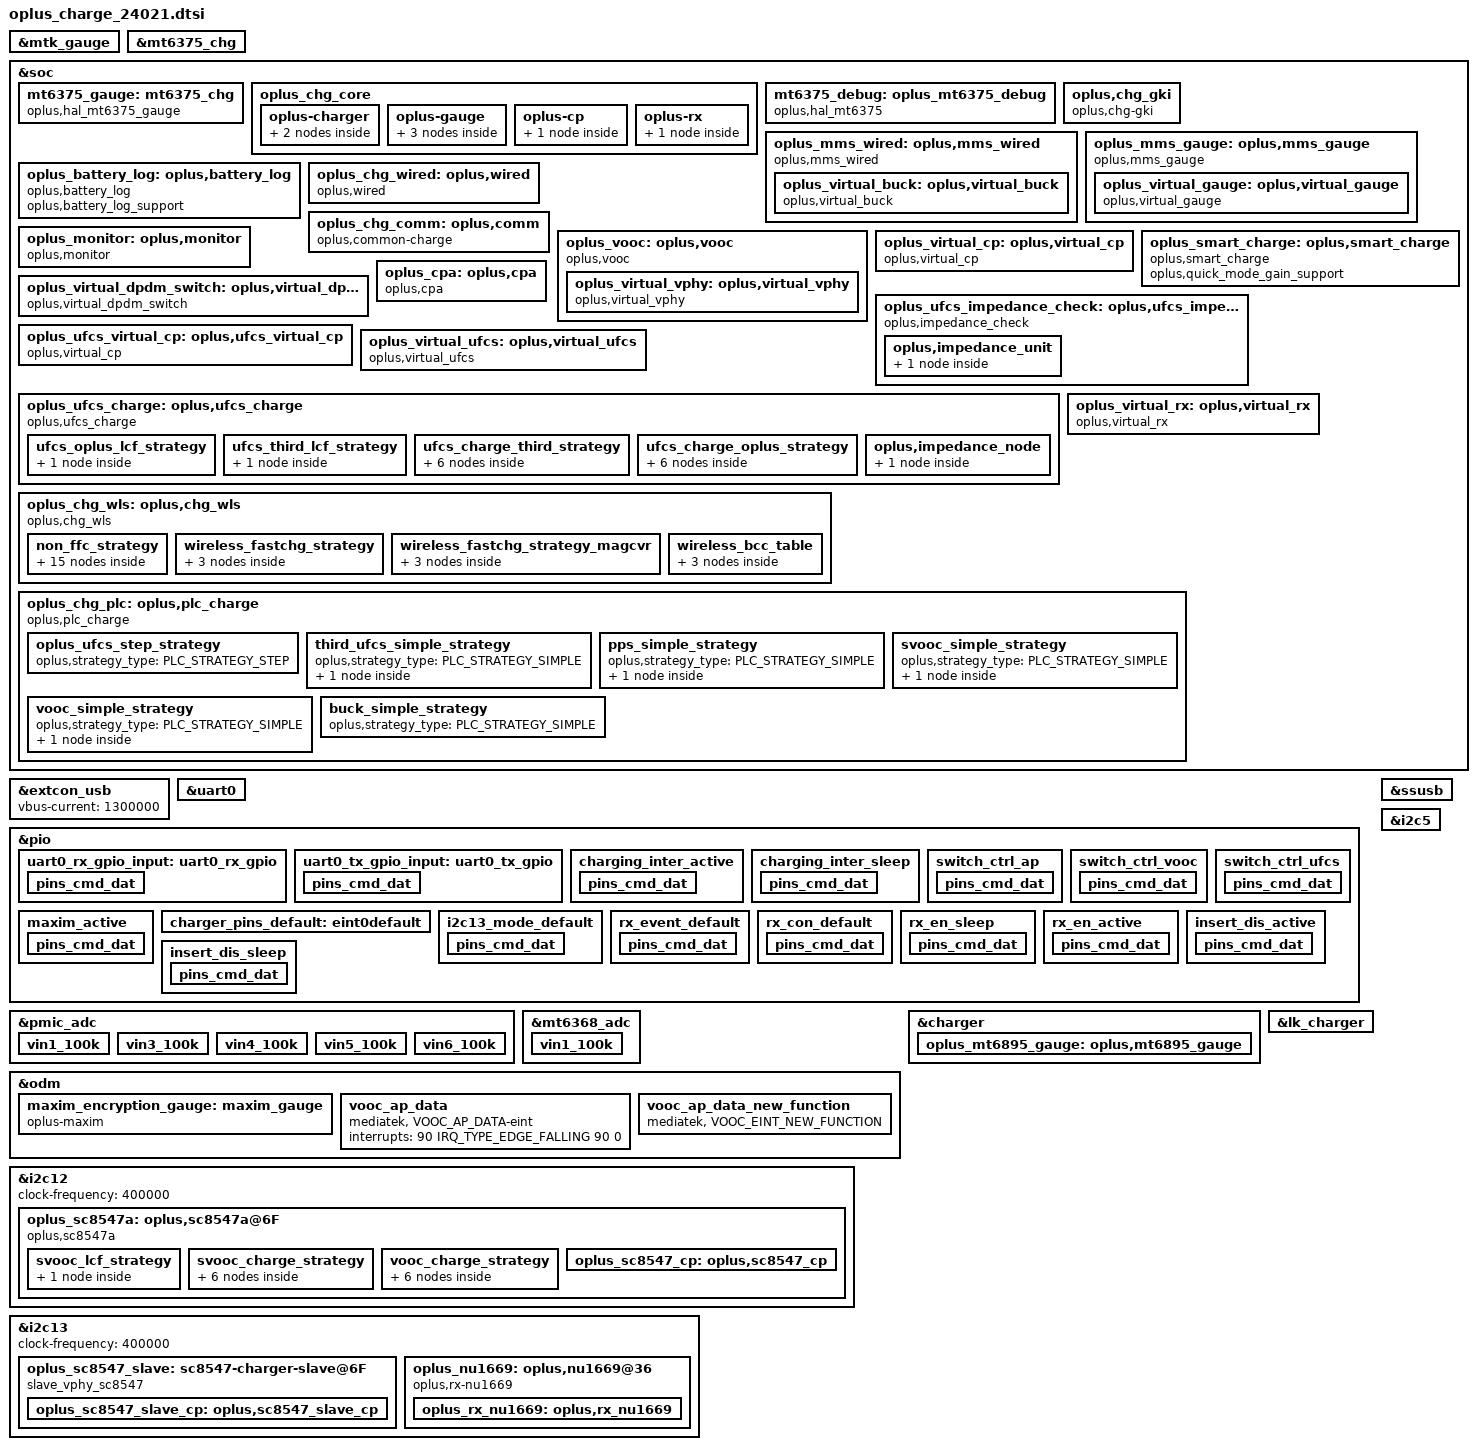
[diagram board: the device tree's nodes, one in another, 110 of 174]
// SPDX-License-Identifier: GPL-2.0-only
/*
* Copyright (C) 2021-2020 Oplus. All rights reserved.
*/
#include <dt-bindings/iio/mt635x-auxadc.h>
#include <dt-bindings/pinctrl/mt6373-pinfunc.h>
#include <dt-bindings/pinctrl/mt65xx.h>
#include "oplus_chg.h"
#include "oplus-chg-24021-fw.dtsi"

&mtk_gauge {
	status = "okay";
	charger = <&mt6375_chg>;
	FUELGAGUE_APPLY = <(1)>;
	IS_SUBBOARD_TEMP_SUPPORT = <(0)>;
	EXTERNAL_AUTHENTICATE =<(1)>;
	Enable_Is_Force_Full = <(1)>;

	active-table = <(5)>;
	r-fg-value = <(1)>;/* R_sense resistance. evb1 use 2; evb2 and later use 1 milliohm */
	com-r-fg-value = <(0)>;/* R_sense compensate resistance. not use COM_R_FG_VALUE */
	RBAT_PULL_DOWN_R = <(24000)>;
	RBAT_PULL_UP_R = <(12000)>;
	RBAT_PULL_UP_VOLT = <(2800)>;
	USE_MORE_PRECISE_NTC_TABLE = <(1)>;
	car-tune-value = <(109)>;
	DIM2_TABLE_DISTINGUISH = <(1)>;
	keep-100-percent-minsoc = <(9500)>;
	aging-factor-diff = <(1)>;
	keep-100-percent = <(2)>;

	#include "bat_setting/mt6897_battery_prop_dim2_ext_24021.dtsi"
	#include "bat_setting/mt6897_battery_table_24021.dtsi"
};

&mt6375_chg {
	chg-tmr = <15>;
	ircmp_v = <0>;
};

&soc {
	mt6375_gauge: mt6375_chg {
		status = "okay";
		compatible = "oplus,hal_mt6375_gauge";

		oplus,ic_type = <OPLUS_CHG_IC_GAUGE>;
		oplus,ic_index = <0>;
		oplus,batt_num = <1>;
		oplus,mtk_gauge_power_sel_support;
		oplus,mtk_gauge_cali_track_support;
	};
};

&extcon_usb {
	vbus-current = <1300000>;
};

&uart0 {
	pinctrl-names = "uart0_rx_gpio", "uart0_tx_gpio";
	pinctrl-0 = <&uart0_rx_gpio_input>;
	pinctrl-1 = <&uart0_tx_gpio_input>;
	status = "okay";
	txpin = <207>;
	rxpin = <208>;
};

&pio {
	uart0_rx_gpio_input: uart0_rx_gpio {
		pins_cmd_dat {
			pinmux = <PINMUX_GPIO208__FUNC_GPIO208>; /* URXD0 */
			input-enable;
			bias-disable;
		};
	};

	uart0_tx_gpio_input: uart0_tx_gpio {
		pins_cmd_dat {
			pinmux = <PINMUX_GPIO207__FUNC_GPIO207>; /* UTXD0 */
			input-enable;
			bias-disable;
		};
	};
};

&pmic_adc {
	vin1_100k {
		channel = <AUXADC_VIN1>;
		pures = <ADC_PURES_100K>;
	};
	vin3_100k {
		channel = <AUXADC_VIN3>;
		pures = <ADC_PURES_100K>;
	};
	vin4_100k {
		channel = <AUXADC_VIN4>;
		pures = <ADC_PURES_100K>;
	};
	vin5_100k {
		channel = <AUXADC_VIN5>;
		pures = <ADC_PURES_100K>;
	};
	vin6_100k {
		channel = <AUXADC_VIN6>;
		pures = <ADC_PURES_100K>;
	};
};

&mt6368_adc {
        vin1_100k {
                channel = <AUXADC_VIN1>;
                pures = <ADC_PURES_100K>;
        };
};

&pio {
	charging_inter_active: charging_inter_active {
		pins_cmd_dat {
			pinmux = <PINMUX_GPIO40__FUNC_GPIO40>;
			input-enable;
			bias-pull-up;
		};
	};

	charging_inter_sleep: charging_inter_sleep {
		pins_cmd_dat {
			pinmux = <PINMUX_GPIO40__FUNC_GPIO40>;
			input-enable;
			bias-disable;
		};
	};
	
	switch_ctrl_ap: switch_ctrl_ap {
		pins_cmd_dat {
			pinmux = <PINMUX_GPIO128__FUNC_GPIO128>;
			output-low;
		};
	};

	switch_ctrl_vooc: switch_ctrl_vooc {
		pins_cmd_dat {
			pinmux = <PINMUX_GPIO128__FUNC_GPIO128>;
			output-high;
		};
	};

	switch_ctrl_ufcs: switch_ctrl_ufcs {
		pins_cmd_dat {
			pinmux = <PINMUX_GPIO128__FUNC_GPIO128>;
			output-high;
		};
	};
};

&soc {
	oplus_chg_core {
		oplus,chg_framework_v2;
		oplus,smart_charging_screenoff;
		oplus,chg_spec_version = <OPLUS_CHG_SPEC_VER_V3P7>;
		oplus,common-charge-icl-support;

		oplus-charger {
			mtk_6895_groups: oplus,mtk_6895-groups {
				functions = <
					OPLUS_IC_FUNC_INIT
					OPLUS_IC_FUNC_EXIT
					OPLUS_IC_FUNC_REG_DUMP
					OPLUS_IC_FUNC_SMT_TEST
					OPLUS_IC_FUNC_BUCK_INPUT_PRESENT
					OPLUS_IC_FUNC_BUCK_INPUT_SUSPEND
					OPLUS_IC_FUNC_BUCK_INPUT_IS_SUSPEND
					OPLUS_IC_FUNC_BUCK_OUTPUT_SUSPEND
					OPLUS_IC_FUNC_BUCK_OUTPUT_IS_SUSPEND
					OPLUS_IC_FUNC_BUCK_SET_ICL
					OPLUS_IC_FUNC_BUCK_GET_ICL
					OPLUS_IC_FUNC_BUCK_SET_FCC
					OPLUS_IC_FUNC_BUCK_SET_FV
					OPLUS_IC_FUNC_BUCK_SET_ITERM
					OPLUS_IC_FUNC_BUCK_GET_INPUT_CURR
					OPLUS_IC_FUNC_BUCK_GET_INPUT_VOL
					OPLUS_IC_FUNC_OTG_BOOST_ENABLE
					OPLUS_IC_FUNC_BUCK_GET_CC_ORIENTATION
					OPLUS_IC_FUNC_BUCK_GET_CHARGER_TYPE
					OPLUS_IC_FUNC_BUCK_RERUN_BC12
					OPLUS_IC_FUNC_BUCK_QC_DETECT_ENABLE
					OPLUS_IC_FUNC_BUCK_SET_QC_CONFIG
					OPLUS_IC_FUNC_BUCK_SET_PD_CONFIG
					OPLUS_IC_FUNC_GET_SHUTDOWN_SOC
					OPLUS_IC_FUNC_BACKUP_SOC
					OPLUS_IC_FUNC_GET_TYPEC_MODE
					OPLUS_IC_FUNC_SET_TYPEC_MODE
					OPLUS_IC_FUNC_GET_TYPEC_ROLE
					OPLUS_IC_FUNC_BUCK_GET_USB_AICL_ENHANCE
					OPLUS_IC_FUNC_BUCK_SET_VINDPM
					OPLUS_IC_FUNC_GET_OTG_ENABLE
					OPLUS_IC_FUNC_BUCK_GET_HW_DETECT
					OPLUS_IC_FUNC_SET_USB_DISCHG_ENABLE
					OPLUS_IC_FUNC_GET_USB_DISCHG_STATUS
					OPLUS_IC_FUNC_IS_OPLUS_SVID
					OPLUS_IC_FUNC_BUCK_GET_USB_BTB_TEMP
					OPLUS_IC_FUNC_BUCK_GET_BATT_BTB_TEMP
					OPLUS_IC_FUNC_BUCK_SET_AICL_POINT
					OPLUS_IC_FUNC_SET_OTG_BOOST_CURR_LIMIT
					OPLUS_IC_FUNC_SET_OTG_BOOST_VOL
					OPLUS_IC_FUNC_BUCK_GET_FV
					OPLUS_IC_FUNC_BUCK_GET_TYPEC_STATE
					OPLUS_IC_FUNC_WLS_BOOST_ENABLE
					OPLUS_IC_FUNC_SET_WLS_BOOST_VOL
					OPLUS_IC_FUNC_SET_WLS_BOOST_CURR_LIMIT
					OPLUS_IC_FUNC_BUCK_WLS_INPUT_SUSPEND
					OPLUS_IC_FUNC_BUCK_SET_WLS_ICL
					OPLUS_IC_FUNC_BUCK_GET_WLS_ICL
					OPLUS_IC_FUNC_BUCK_GET_WLS_INPUT_CURR
					OPLUS_IC_FUNC_BUCK_GET_WLS_INPUT_VOL
					OPLUS_IC_FUNC_BUCK_WLS_AICL_ENABLE
					OPLUS_IC_FUNC_BUCK_WLS_AICL_RERUN
					OPLUS_IC_FUNC_BUCK_DIS_INSERT_DETECT
				>;
				virqs = <
					OPLUS_IC_VIRQ_ERR
					OPLUS_IC_VIRQ_CC_DETECT
					OPLUS_IC_VIRQ_PLUGIN
					OPLUS_IC_VIRQ_CC_CHANGED
					OPLUS_IC_VIRQ_CHG_TYPE_CHANGE
					OPLUS_IC_VIRQ_OTG_ENABLE
					OPLUS_IC_VIRQ_SVID
					OPLUS_IC_VIRQ_TYPEC_STATE
				>;
			};


			mt6375_debug_groups: oplus,mt6375_debug_groups {
				functions = <
					OPLUS_IC_FUNC_INIT
					OPLUS_IC_FUNC_EXIT
				>;
				virqs = <
					OPLUS_IC_VIRQ_ERR
				>;
			};
		};

		oplus-gauge {
			mt6375_gauge_groups: oplus,mt6375_gauge_groups {
				functions = <
					OPLUS_IC_FUNC_INIT
					OPLUS_IC_FUNC_EXIT
					OPLUS_IC_FUNC_REG_DUMP
					OPLUS_IC_FUNC_SMT_TEST
					OPLUS_IC_FUNC_GAUGE_GET_BATT_VOL
					OPLUS_IC_FUNC_GAUGE_GET_BATT_MAX
					OPLUS_IC_FUNC_GAUGE_GET_BATT_MIN
					OPLUS_IC_FUNC_GAUGE_GET_BATT_CURR
					OPLUS_IC_FUNC_GAUGE_GET_BATT_TEMP
					OPLUS_IC_FUNC_GAUGE_GET_BATT_SOC
					OPLUS_IC_FUNC_GAUGE_GET_BATT_FCC
					OPLUS_IC_FUNC_GAUGE_GET_BATT_CC
					OPLUS_IC_FUNC_GAUGE_GET_BATT_RM
					OPLUS_IC_FUNC_GAUGE_GET_BATT_SOH
					OPLUS_IC_FUNC_GAUGE_GET_BATT_HMAC
					OPLUS_IC_FUNC_GAUGE_SET_BATT_FULL
					OPLUS_IC_FUNC_GAUGE_UPDATE_DOD0
					OPLUS_IC_FUNC_GAUGE_UPDATE_SOC_SMOOTH
					OPLUS_IC_FUNC_GAUGE_GET_CB_STATUS
					OPLUS_IC_FUNC_GAUGE_GET_BATT_NUM
					OPLUS_IC_FUNC_GAUGE_GET_DEVICE_TYPE
					OPLUS_IC_FUNC_GAUGE_GET_DEVICE_TYPE_FOR_VOOC
					OPLUS_IC_FUNC_GAUGE_GET_BATT_FCC
					OPLUS_IC_FUNC_GAUGE_GET_BATT_FC
					OPLUS_IC_FUNC_GAUGE_GET_BATT_QM
					OPLUS_IC_FUNC_GAUGE_GET_BATT_PD
					OPLUS_IC_FUNC_GAUGE_GET_BATT_RCU
					OPLUS_IC_FUNC_GAUGE_GET_BATT_RCF
					OPLUS_IC_FUNC_GAUGE_GET_BATT_FCU
					OPLUS_IC_FUNC_GAUGE_GET_BATT_FCF
					OPLUS_IC_FUNC_GAUGE_GET_BATT_SOU
					OPLUS_IC_FUNC_GAUGE_GET_BATT_DO0
					OPLUS_IC_FUNC_GAUGE_GET_BATT_DOE
					OPLUS_IC_FUNC_GAUGE_GET_BATT_TRM
					OPLUS_IC_FUNC_GAUGE_GET_BATT_PC
					OPLUS_IC_FUNC_GAUGE_GET_BATT_QS
					OPLUS_IC_FUNC_GAUGE_IS_SUSPEND
					OPLUS_IC_FUNC_GAUGE_GET_BCC_PARMS
					OPLUS_IC_FUNC_GAUGE_FASTCHG_UPDATE_BCC_PARMS
					OPLUS_IC_FUNC_GAUGE_GET_PREV_BCC_PARMS
					OPLUS_IC_FUNC_GAUGE_SET_BCC_PARMS
					OPLUS_IC_FUNC_GAUGE_SET_PROTECT_CHECK
					OPLUS_IC_FUNC_GAUGE_GET_AFI_UPDATE_DONE
					OPLUS_IC_FUNC_GAUGE_CHECK_RESET
					OPLUS_IC_FUNC_GAUGE_GET_DEVICE_TYPE_FOR_BCC
					OPLUS_IC_FUNC_GAUGE_GET_DOD0
					OPLUS_IC_FUNC_GAUGE_GET_DOD0_PASSED_Q
					OPLUS_IC_FUNC_GAUGE_GET_QMAX
					OPLUS_IC_FUNC_GAUGE_GET_QMAX_PASSED_Q
					OPLUS_IC_FUNC_GAUGE_SET_BATTERY_CURVE
					OPLUS_IC_FUNC_GAUGE_GET_GAUGE_CAR_C
				>;
				virqs = <
					OPLUS_IC_VIRQ_ERR
					OPLUS_IC_VIRQ_OFFLINE
					OPLUS_IC_VIRQ_RESUME
				>;
			};

			mt6895_gauge_groups: oplus,mt6895_gauge_groups {
				functions = <
					OPLUS_IC_FUNC_INIT
					OPLUS_IC_FUNC_EXIT
					OPLUS_IC_FUNC_GAUGE_GET_SUBBOARD_TEMP
				>;
				virqs = <
					OPLUS_IC_VIRQ_ERR
				>;
			};

			maxim_encryption_gauge_groups: oplus,maxim_encryption_gauge_groups {
				functions = <
					OPLUS_IC_FUNC_INIT
					OPLUS_IC_FUNC_EXIT
					OPLUS_IC_FUNC_GAUGE_GET_BATT_AUTH
				>;
				virqs = <
					OPLUS_IC_VIRQ_ERR
				>;
			};
		};
		oplus-cp {
			sc8547_cp_groups: oplus,cp_groups {
			functions = <
					OPLUS_IC_FUNC_INIT
					OPLUS_IC_FUNC_EXIT
					OPLUS_IC_FUNC_REG_DUMP
					OPLUS_IC_FUNC_SMT_TEST
					OPLUS_IC_FUNC_CP_ENABLE
					OPLUS_IC_FUNC_CP_HW_INTI
					OPLUS_IC_FUNC_CP_SET_WORK_START
					OPLUS_IC_FUNC_CP_CHECK_WORK_MODE_SUPPORT
					OPLUS_IC_FUNC_CP_SET_WORK_MODE
					OPLUS_IC_FUNC_CP_GET_WORK_MODE
					OPLUS_IC_FUNC_CP_GET_VIN
					OPLUS_IC_FUNC_CP_GET_IIN
					OPLUS_IC_FUNC_CP_SET_IIN
					OPLUS_IC_FUNC_CP_GET_VOUT
					OPLUS_IC_FUNC_CP_GET_IOUT
					OPLUS_IC_FUNC_CP_GET_VAC
					OPLUS_IC_FUNC_CP_GET_WORK_STATUS
					OPLUS_IC_FUNC_CP_SET_ADC_ENABLE
					OPLUS_IC_FUNC_CP_WATCHDOG_ENABLE
					OPLUS_IC_FUNC_CP_SET_UCP_DISABLE
				>;
				virqs = <
					OPLUS_IC_VIRQ_ERR
					OPLUS_IC_VIRQ_ONLINE
					OPLUS_IC_VIRQ_OFFLINE
				>;
			};
		};

		oplus-rx {
			nu1669_rx_groups: oplus,rx_groups {
				functions = <
					OPLUS_IC_FUNC_INIT
					OPLUS_IC_FUNC_EXIT
					OPLUS_IC_FUNC_REG_DUMP
					OPLUS_IC_FUNC_SMT_TEST
					OPLUS_IC_FUNC_RX_SET_ENABLE
					OPLUS_IC_FUNC_RX_IS_ENABLE
					OPLUS_IC_FUNC_RX_IS_CONNECTED
					OPLUS_IC_FUNC_RX_GET_VOUT
					OPLUS_IC_FUNC_RX_SET_VOUT
					OPLUS_IC_FUNC_RX_GET_VRECT
					OPLUS_IC_FUNC_RX_GET_IOUT
					OPLUS_IC_FUNC_RX_GET_TRX_VOL
					OPLUS_IC_FUNC_RX_GET_TRX_CURR
					OPLUS_IC_FUNC_RX_GET_CEP_COUNT
					OPLUS_IC_FUNC_RX_GET_CEP_VAL
					OPLUS_IC_FUNC_RX_GET_WORK_FREQ
					OPLUS_IC_FUNC_RX_GET_RX_MODE
					OPLUS_IC_FUNC_RX_SET_RX_MODE
					OPLUS_IC_FUNC_RX_SET_DCDC_ENABLE
					OPLUS_IC_FUNC_RX_SET_TRX_ENABLE
					OPLUS_IC_FUNC_RX_SET_TRX_START
					OPLUS_IC_FUNC_RX_GET_TRX_STATUS
					OPLUS_IC_FUNC_RX_GET_TRX_ERR
					OPLUS_IC_FUNC_RX_GET_HEADROOM
					OPLUS_IC_FUNC_RX_SET_HEADROOM
					OPLUS_IC_FUNC_RX_SEND_MATCH_Q
					OPLUS_IC_FUNC_RX_SET_FOD_PARM
					OPLUS_IC_FUNC_RX_SEND_MSG
					OPLUS_IC_FUNC_RX_REG_MSG_CALLBACK
					OPLUS_IC_FUNC_RX_GET_RX_VERSION
					OPLUS_IC_FUNC_RX_GET_TRX_VERSION
					OPLUS_IC_FUNC_RX_UPGRADE_FW_BY_BUF
					OPLUS_IC_FUNC_RX_UPGRADE_FW_BY_IMG
					OPLUS_IC_FUNC_RX_CHECK_CONNECT
					OPLUS_IC_FUNC_RX_GET_EVENT_CODE
					OPLUS_IC_FUNC_RX_GET_BRIDGE_MODE
					OPLUS_IC_FUNC_RX_DIS_INSERT
					OPLUS_IC_FUNC_RX_STANDBY_CONFIG
					OPLUS_IC_FUNC_RX_SET_COMU
					OPLUS_IC_FUNC_RX_GET_TX_ID
				>;
				virqs = <
					OPLUS_IC_VIRQ_ERR
					OPLUS_IC_VIRQ_PRESENT
					OPLUS_IC_VIRQ_ONLINE
					OPLUS_IC_VIRQ_OFFLINE
					OPLUS_IC_VIRQ_EVENT_CHANGED
				>;
			};
		};
	};
};

&soc {
	mt6375_debug: oplus_mt6375_debug {
		status = "okay";
		compatible = "oplus,hal_mt6375";

		oplus,tcpc_name = "type_c_port0";

		oplus,ic_type = <OPLUS_CHG_IC_BUCK>;
		oplus,ic_index = <2>;
	};
};

&odm {
	maxim_encryption_gauge: maxim_gauge {
		status = "okay";
		compatible = "oplus-maxim";
		pinctrl-names = "maxim_active";
		pinctrl-0 = <&maxim_active>;
		support_encryption_in_lk;
		data-gpio = <&pio 23 0x00>;
		gpio-addr-set-out = <0x10005004>;
		gpio-addr-set-in = <0x10005008>;
		gpio-addr-level_high = <0x10005104>;
		gpio-addr-level_low = <0x10005108>;
		gpio-addr-data-in = <0x10005200>;
		gpio-addr-offset = <0x17>;

		oplus,batt_info = /bits/ 8 <0x36 0x31 0x31 0x33 0x30 0x33 0x30 0x30 0x30 0x31 0x34 0x35
					    0x36 0x31 0x31 0x33 0x30 0x33 0x30 0x30 0x30 0x31 0x34 0x34>;

		oplus,ic_type = <OPLUS_CHG_IC_GAUGE>;
		oplus,ic_index = <2>;
	};
};

&pio {
	maxim_active: maxim_active {
		pins_cmd_dat {
			pinmux = <PINMUX_GPIO23__FUNC_GPIO23>;
			//slew-rate = <1>;
			drive-strength = <6>;
			bias-pull-up;
		};
	};
};

&soc {
	oplus,chg_gki {
		compatible = "oplus,chg-gki";
	};
};

&charger {
	io-channels = <&mt6368_adc (ADC_PURES_100K_MASK | AUXADC_VIN1)>, <&pmic_adc AUXADC_VIN5>, <&pmic_adc AUXADC_VIN6>, <&pmic_adc AUXADC_VIN1>;
	io-channel-names = "auxadc1-ntc_sub_bat_tem", "auxadc5-chargeric_temp", "auxadc5_batt_btb_temp", "auxadc6_usb_btb_temp";

	pinctrl-names = "default";
	pinctrl-0 = <&charger_pins_default>;
	oplus,support_ntc_01c_precision;
	oplus,support_subboard_ntc;
	max_charger_voltage = <15000000>;
	/* ntc_resistance:100k internal_pull_up:100k voltage:1.84v */
	oplus,ntc_temp_volt_1840mv;

	oplus,usb_aicl_enhance;

	/* usbtemp dischg use pmic regulator to set vbus down */
	oplus,support_usbtemp_dischg_reg_configurable;
	oplus,usbtemp_dischg_reg_addr = <0x989>;
	oplus,usbtemp_dischg_reg_mask = <0x7>;
	oplus,usbtemp_dischg_enable = <0x2>;
	oplus,usbtemp_dischg_disable = <0x0>;

	oplus,ic_type = <OPLUS_CHG_IC_BUCK>;
	oplus,ic_index = <0>;

	oplus_mt6895_gauge: oplus,mt6895_gauge {
		oplus,ic_type = <OPLUS_CHG_IC_GAUGE>;
		oplus,ic_index = <1>;
	};
};

&odm {
	vooc_ap_data:vooc_ap_data {
		compatible = "mediatek, VOOC_AP_DATA-eint";
		interrupts = <90 IRQ_TYPE_EDGE_FALLING 90 0>;
	};
	vooc_ap_data_new_function:vooc_ap_data_new_function {
		compatible = "mediatek, VOOC_EINT_NEW_FUNCTION";
	};
};

&pio {
	charger_pins_default: eint0default {
	};
};

&lk_charger {
	en_vol_ctrl_vibrate = <3200>;
	support_tuv_authentication;
	high-temp-scheme;
	charger_no_wiress;
	support_battery_type = <2>;
	support_maxim_battery_authentication;
	data-gpio = <23>;
	//cpu-id = <7>;
	//key-id = <1>;
	oplus,batt_info = /bits/ 8 <0x36 0x31 0x31 0x33 0x30 0x33 0x30 0x30 0x30 0x31 0x34 0x35
				    0x36 0x31 0x31 0x33 0x30 0x33 0x30 0x30 0x30 0x31 0x34 0x34>;
	oplus,batt_resource_info = /bits/ 8 <0 1>;
	sub_board_temp_support;
	over_high_temp_thr = <60>;
	sub_board_adc_channel = <18>;		/* AUXADC_CHAN_VIN1 in LK, Use the MT6368 PMIC */
	sub_board_adc_pmic = <1>;		/* Vivien use the MT6368 Pmic, in lk2 it's name is "second_pmic_sdmadc" */
	sub_board_adc_pull_up_voltage = <1840>;
	sub_board_adc_pures = <0>;	/* Vivien config as SDMADC_100K */

	support_sdp_screenoff;
	sdp_screenon_voltage = <3250>;
	support_quickboot_charge;
	mt6375_wireless_prj_shipmode_support; /* use MT6375 and support wireless prj,need to configure this to enter shipmode success */

	/* mt6989 start */
	led-brightness = <102>;
	/* mt6989, such as max_charger_voltage to max-charger-voltage */
	max-charger-voltage = <15000000>;
	boot-battery-voltage = <3350000>;
	usb-charger-current = <500000>;
	ac-charger-current = <2050000>;
	ac-charger-input-current = <1500000>;
	non-std-ac-charger-current = <750000>;
	charging-host-charger-current = <1500000>;
	ta-ac-charger-current = <1500000>;
	pd-charger-current = <500000>;
	/* mt6989 end */
};

&soc {
	oplus_mms_wired: oplus,mms_wired {
		compatible = "oplus,mms_wired";
		oplus,buck_ic = <&oplus_virtual_buck>;
		oplus,voocphy_ic = <&oplus_virtual_vphy>;
		oplus,adc_info_name = "100k_1840mv";
		oplus_spec,usbtemp_batttemp_gap = <12>;
		high-temp-scheme;

		/* support for V2.0 usbtemp protect. */
		oplus,support_usbtemp_protect_v2;
		oplus,support_wlsotg_non_coexistence;
		oplus_spec,usbtemp_batt_temp_low = <50>;
		oplus_spec,usbtemp_batt_temp_high = <50>;
		oplus_spec,usbtemp_batt_temp_over_hot = <60>;
		oplus_spec,usbtemp_ntc_temp_low = <57>;
		oplus_spec,usbtemp_ntc_temp_high = <69>;
		oplus_spec,usbtemp_temp_gap_low_with_batt_temp = <7>;
		oplus_spec,usbtemp_temp_gap_with_batt_temp_in_over_hot = <15>;
		oplus_spec,usbtemp_temp_gap_high_with_batt_temp = <12>;
		oplus_spec,usbtemp_temp_gap_low_without_batt_temp = <12>;
		oplus_spec,usbtemp_temp_gap_high_without_batt_temp = <24>;
		oplus_spec.usbtemp_rise_fast_temp_low = <3>;
		oplus_spec.usbtemp_rise_fast_temp_high = <3>;
		oplus_spec.usbtemp_rise_fast_temp_count_low = <30>;
		oplus_spec.usbtemp_rise_fast_temp_count_high = <20>;
		oplus_spec,usbtemp_cool_down_ntc_low = <54>;
		oplus_spec,usbtemp_cool_down_ntc_high = <65>;
		oplus_spec,usbtemp_cool_down_gap_low = <12>;
		oplus_spec,usbtemp_cool_down_gap_high = <20>;
		oplus_spec,usbtemp_cool_down_recover_ntc_low = <48>;
		oplus_spec,usbtemp_cool_down_recover_ntc_high = <60>;
		oplus_spec,usbtemp_cool_down_recover_gap_low = <6>;
		oplus_spec,usbtemp_cool_down_recover_gap_high = <15>;

		oplus_virtual_buck: oplus,virtual_buck {
			compatible = "oplus,virtual_buck";
			oplus,buck_ic = <&charger &mt6375_debug>;
			oplus,buck_ic_index = <0 1>;
			oplus,buck_ic_current_ratio = <100 0>;
			oplus,buck_ic_connect = <OPLUS_CHG_IC_CONNECT_PARALLEL>;
			oplus,main_charger = <0>;
			oplus,buck_ic_func_group = <&mtk_6895_groups &mt6375_debug_groups>;

			oplus,ic_type = <OPLUS_CHG_IC_VIRTUAL_BUCK>;
			oplus,ic_index = <0>;

			io-channels = <&pmic_adc AUXADC_VIN3>, <&pmic_adc AUXADC_VIN4>;
			io-channel-names = "usb_temp_adc_l", "usb_temp_adc_r";

			oplus,uart_tx-gpio = <&pio 207 0x00>;
			oplus,uart_rx-gpio = <&pio 208 0x00>;
		};
	};

	oplus_mms_gauge: oplus,mms_gauge {
		compatible = "oplus,mms_gauge";
		oplus,gauge_ic = <&oplus_virtual_gauge>;
		oplus,voocphy_ic = <&oplus_virtual_vphy>;
		oplus,topic-update-interval = <10000>;
		oplus,support_subboard_ntc;

		oplus_virtual_gauge: oplus,virtual_gauge {
			compatible = "oplus,virtual_gauge";
			oplus,gauge_ic = <&mt6375_gauge &oplus_mt6895_gauge &maxim_encryption_gauge>;
			oplus,gauge_ic_index = <0 1 2>;
			oplus,gauge_ic_func_group = <&mt6375_gauge_groups &mt6895_gauge_groups &maxim_encryption_gauge_groups>;
			oplus,batt_capacity_mah = <5800>;
			oplus,ic_type = <OPLUS_CHG_IC_VIRTUAL_GAUGE>;
			oplus,ic_index = <0>;
		};
	};
};

&soc {
	oplus_battery_log: oplus,battery_log {
		compatible = "oplus,battery_log";

		oplus,battery_log_support;
	};

	oplus_chg_wired: oplus,wired {
		compatible = "oplus,wired";

		oplus,vooc-support;

		oplus_spec,vbatt_pdqc_to_5v_thr = <4500>;
		oplus_spec,vbatt_pdqc_to_9v_thr = <4500>;
		oplus_spec,pd-iclmax-ma = <1500>;
		oplus_spec,qc-iclmax-ma = <1500>;
		oplus_spec,non-standard-ibatmax-ma = <500>;
		oplus_spec,input-power-mw = <
			500	    	/* OPLUS_WIRED_CHG_MODE_UNKNOWN */
			2500		/* OPLUS_WIRED_CHG_MODE_SDP */
			7500		/* OPLUS_WIRED_CHG_MODE_CDP */
			10000		/* OPLUS_WIRED_CHG_MODE_DCP */
			15000		/* OPLUS_WIRED_CHG_MODE_VOOC */
			13500		/* OPLUS_WIRED_CHG_MODE_QC */
			13500		/* OPLUS_WIRED_CHG_MODE_PD */
		>;
		oplus_spec,led_on-fccmax-ma = <0 1443 2538 3300 3300 3300 3300 1000 0>;
		oplus_spec,fccmax-ma-lv = <
			0 1410 2200 2200 2200 2200 2200 2200 0	/* OPLUS_WIRED_CHG_MODE_UNKNOWN */
			0 600  600  600  600  600  600  600  0	/* OPLUS_WIRED_CHG_MODE_SDP */
			0 1410 1600 1600 1600 1600 1600 1600 0	/* OPLUS_WIRED_CHG_MODE_CDP */
			0 1410 2200 2200 2200 2200 2200 2200 0	/* OPLUS_WIRED_CHG_MODE_DCP */
			0 1410 3300 3300 3300 3300 3300 3102 0	/* OPLUS_WIRED_CHG_MODE_VOOC */
			0 1410 3300 3300 3300 3300 3300 3102 0	/* OPLUS_WIRED_CHG_MODE_QC */
			0 1410 3300 3300 3300 3300 3300 3102 0	/* OPLUS_WIRED_CHG_MODE_PD */
		>;
		oplus_spec,fccmax-ma-hv = <
			0 1410 2200 2200 2200 2200 2200 2200 0	/* OPLUS_WIRED_CHG_MODE_UNKNOWN */
			0 600  600  600  600  600  600  600  0	/* OPLUS_WIRED_CHG_MODE_SDP */
			0 1410 1600 1600 1600 1600 1600 1600 0	/* OPLUS_WIRED_CHG_MODE_CDP */
			0 1410 2200 2200 2200 2200 2200 2200 0	/* OPLUS_WIRED_CHG_MODE_DCP */
			0 1410 3300 3300 3300 3300 3300 3102 0	/* OPLUS_WIRED_CHG_MODE_VOOC */
			0 1410 3300 3300 3300 3300 3300 3102 0	/* OPLUS_WIRED_CHG_MODE_QC */
			0 1410 3300 3300 3300 3300 3300 3102 0	/* OPLUS_WIRED_CHG_MODE_PD */
		>;

		oplus_spec,cool_down_sale_pdqc_vol_mv = <5000>;
		oplus_spec,cool_down_sale_pdqc_curr_ma = <1200>;
		oplus_spec,cool_down_pdqc_vol_mv = <5000 5000 5000 9000>;
		oplus_spec,cool_down_pdqc_curr_ma = <1200 1500 2000 1500>;
		oplus_spec,cool_down_vooc_curr_ma = <1200 1500 2000 2500 3000 3000>;
		oplus_spec,cool_down_normal_curr_ma = <1200 1500 2000>;

		oplus_spec,vbus_ov_thr_mv = <11000 11000>;
		oplus_spec,vbus_uv_thr_mv = <4300 4300>;

		/* first data is strategy used temp type */
		oplus,vooc_strategy_name = "cgcl";
		oplus,vooc_strategy_data = <OPLUS_STRATEGY_USE_BATT_TEMP
					    0   350 3000 1 0
					    330 370 3000 2 0
					    350 440 2200 2 1>;
	};

	oplus_chg_comm: oplus,comm {
		compatible = "oplus,common-charge";
		oplus_spec,batt-them-thr = <(-100) 0 50 120 160 350 450 530>;
		oplus_spec,iterm-ma = <292>; /* 4880*0.05+10 */
		oplus_spec,removed_bat_decidegc = <390>; /*-39 degree*/
		oplus_spec,fv-mv = <4490 4490 4490 4490 4490 4490 4470 4130 4130>;
		oplus_spec,sw-fv-mv = <4440 4440 4440 4440 4440 4440 4420 4080 4080>;
		oplus_spec,hw-fv-inc-mv = <0 18 18 18 18 18 18 18 0>;
		oplus_spec,sw-over-fv-mv = <4500 4500 4500 4500 4500 4500 4480 4140 4140>;
		oplus_spec,sw-over-fv-dec-mv = <8>;
		oplus_spec,non-standard-sw-fv-mv = <3930>;
		oplus_spec,non-standard-fv-mv = <3980>;
		oplus_spec,non-standard-hw-fv-inc-mv = <18>;
		oplus_spec,non-standard-sw-over-fv-mv = <3990>;
		oplus_spec,non-standard-vbatdet-mv = <3680>;
		oplus_spec,wired-vbatdet-mv = <0 4190 4290 4390 4390 4390 4370 4030 0>;
		oplus_spec,wls-vbatdet-mv = <0 4190 4290 4390 4390 4390 4370 4030 0>;
		oplus_spec,fcc-gear-thr-mv = <4180>;
		oplus_spec,vbatt-ov-thr-mv = <4600>;

		oplus_spec,full_pre_ffc_judge;
		oplus_spec,full-pre-ffc-mv = <4485>;
		oplus_spec,ffc-temp-thr = <120 210 350 440>;
		oplus_spec,wired-ffc-step-max = <2>;
		oplus_spec,wired-ffc-fv-mv = <4630 4630>;

		oplus_spec,wired-ffc-fv-cutoff-mv = <4560 4550 4515
						     4550 4540 4500>;
		oplus_spec,wired-ffc-fcc-ma = <1500 1500 1500
					       1000 1000 1000>;
		oplus_spec,wired-ffc-fcc-cutoff-ma = <1300 1300 1300
						      900 900 900>;
		/* 2s battery */
		oplus_spec,wls-ffc-step-max = <2>;
		oplus_spec,wls-ffc-fv-mv = <4630 4630>;
		oplus_spec,wls-ffc-fv-cutoff-mv = <4560 4550 4515
						     4550 4540 4500>;
		oplus_spec,wls-ffc-icl-ma = <1150 1150 1150
					     750 750 750>;
		oplus_spec,wls-ffc-fcc-ma = <1500 1500 1500
					     1000 1000 1000>;
		oplus_spec,wls-ffc-fcc-cutoff-ma = <1300 1300 1300
						900 900 900>;
		oplus_spec,vbat_uv_thr_mv = <3300>;
		oplus_spec,vbat_charging_uv_thr_mv = <3200>;

		/*If use subboard NTC as battery temp, config it as 20, otherwise 0 */
		oplus_spec,tbatt_power_off_cali_temp = <0>;
		oplus,vooc_show_ui_soc_decimal;
		oplus_spec,poweroff_high_batt_temp = <720>;
		oplus_spec,poweroff_emergency_batt_temp = <770>;
		oplus,ui_soc_decimal_speedmin = <20>;
		oplus,gauge_stuck_jump_support;
		oplus,gauge_stuck_threshold = <15>;
		oplus,gauge_stuck_time = <50>;
	};

	oplus_monitor: oplus,monitor {
		compatible = "oplus,monitor";
		oplus,topic-update-interval = <60000>;

		track,fast_chg_break_t_thd = <1000>;
		track,general_chg_break_t_thd = <200>;
		track,voocphy_type = <3>;
		track,wired_max_power = <80000>;
		track,wired_fast_chg_scheme = <2>;
	};

	oplus_vooc: oplus,vooc {
		compatible = "oplus,vooc";
		oplus,vooc_ic = <&oplus_virtual_vphy>;

		oplus_spec,vooc_soc_range = <50 75 85>;
		oplus_spec,vooc_temp_range = <50 120 180 350 450>;

		oplus,vooc_data_width = <7>;
		oplus,vooc_curr_max = <CP_CURR_LIMIT_7BIT_15_0A>; /* 80W: 11V 7.3A(IBUS *2) */
		oplus,vooc_power_max_w = <80>;
		oplus,vooc_project = <7>;
		oplus,vooc_curr_table_type = <VOOC_CP_CURR_TABLE>;
		oplus,voocphy_support = <3>; /* AP_DUAL_CP_VOOCPHY */
		oplus,support_fake_vooc_check;
		oplus,subboard_ntc_abnormal_current = <4000>;
		oplus,cp_cooldown_limit_percent_75 = <CP_CURR_LIMIT_7BIT_8_0A>;
		oplus,cp_cooldown_limit_percent_85 = <CP_CURR_LIMIT_7BIT_4_0A>;

		oplus,abnormal_adapter_current = <CP_CURR_LIMIT_7BIT_15_0A CP_CURR_LIMIT_7BIT_15_0A
						CP_CURR_LIMIT_7BIT_12_6A CP_CURR_LIMIT_7BIT_12_6A
						CP_CURR_LIMIT_7BIT_10_0A CP_CURR_LIMIT_7BIT_10_0A
						CP_CURR_LIMIT_7BIT_8_0A CP_CURR_LIMIT_7BIT_8_0A
						CP_CURR_LIMIT_7BIT_6_0A CP_CURR_LIMIT_7BIT_6_0A
						CP_CURR_LIMIT_7BIT_4_0A CP_CURR_LIMIT_7BIT_4_0A>;

		oplus,abnormal_over_80w_adapter_current = <CP_CURR_LIMIT_7BIT_15_0A CP_CURR_LIMIT_7BIT_15_0A
						CP_CURR_LIMIT_7BIT_14_0A CP_CURR_LIMIT_7BIT_14_0A
						CP_CURR_LIMIT_7BIT_12_0A CP_CURR_LIMIT_7BIT_12_0A
						CP_CURR_LIMIT_7BIT_10_0A CP_CURR_LIMIT_7BIT_10_0A
						CP_CURR_LIMIT_7BIT_8_0A CP_CURR_LIMIT_7BIT_8_0A
						CP_CURR_LIMIT_7BIT_6_0A CP_CURR_LIMIT_7BIT_6_0A
						CP_CURR_LIMIT_7BIT_4_0A CP_CURR_LIMIT_7BIT_4_0A>;

		/* first data is strategy used temp type */
		oplus,general_strategy_name = "cgcl";
		oplus,general_strategy_data = < OPLUS_STRATEGY_USE_SHELL_TEMP
						0   385 CP_CURR_LIMIT_7BIT_15_0A 1 0
						375 395 CP_CURR_LIMIT_7BIT_12_6A 2 0
						385 420 CP_CURR_LIMIT_7BIT_8_0A 3 1
						410 440 CP_CURR_LIMIT_7BIT_6_0A 3 2 >;

		oplus,plc_strategy-data = <&buck_simple_strategy &svooc_simple_strategy &vooc_simple_strategy>;
		oplus,plc_strategy-names = "default", "svooc", "vooc";

		oplus,bypass_strategy_name = "cgcl";
		oplus,bypass_strategy_data = <OPLUS_STRATEGY_USE_SHELL_TEMP
						0   350 CP_CURR_LIMIT_7BIT_6_0A  1 0
						340 380 CP_CURR_LIMIT_7BIT_5_0A  2 0
						370 440 CP_CURR_LIMIT_7BIT_4_0A  2 1>;

		oplus_virtual_vphy: oplus,virtual_vphy {
			compatible = "oplus,virtual_vphy";
			oplus,vphy_ic = <&oplus_sc8547a>;
			oplus,dpdm_switch_ic = <&oplus_virtual_dpdm_switch>;

			oplus,ic_type = <OPLUS_CHG_IC_VIRTUAL_VPHY>;
			oplus,ic_index = <0>;
		};
	};

	oplus_virtual_cp: oplus,virtual_cp {
		compatible = "oplus,virtual_cp";

		oplus,ic_type = <OPLUS_CHG_IC_VIRTUAL_CP>;
		oplus,ic_index = <0>;

		oplus,cp_ic = <&oplus_sc8547_cp &oplus_sc8547_slave_cp>;
		oplus,input_curr_max_ma = <3000 3000>;

		oplus,cp_ic_connect = <OPLUS_CHG_IC_CONNECT_PARALLEL>;
		oplus,main_cp = <0>;

		oplus,reg_proc_node;
	};

	oplus_virtual_dpdm_switch: oplus,virtual_dpdm_switch {
		compatible = "oplus,virtual_dpdm_switch";

		oplus,ic_type = <OPLUS_CHG_IC_MISC>;
		oplus,ic_index = <0>;

		oplus,switch_ctrl-gpio = <&pio 128 0x00>;
		pinctrl-names = "switch_ctrl_ap", "switch_ctrl_vooc", "switch_ctrl_ufcs";
		pinctrl-0 = <&switch_ctrl_ap>;
		pinctrl-1 = <&switch_ctrl_vooc>;
		pinctrl-2 = <&switch_ctrl_ufcs>;
	};
	oplus_smart_charge: oplus,smart_charge {
		compatible = "oplus,smart_charge";
		oplus,quick_mode_gain_support;
	};
};

&i2c12 {
	status = "okay";
	clock-frequency = <400000>;
	oplus_sc8547a: oplus,sc8547a@6F {
		status = "okay";
		compatible = "oplus,sc8547a";
		reg = <0x6F>;

		oplus,use_vooc_phy;
		oplus,use_ufcs_phy;
		oplus_spec,irq_gpio = <&pio 40 0x00>;
		interrupt-parent = <&pio>;
		interrupts = <9 0>;

		pinctrl-names = "charging_inter_active", "charging_inter_sleep";
		pinctrl-0 = <&charging_inter_active>;
		pinctrl-1 = <&charging_inter_sleep>;

		oplus,ic_type = <OPLUS_CHG_IC_VPHY>;
		oplus,ic_index = <0>;
		oplus,vooc-version = <VOOC_VERSION_5_0>;

		ocp_reg = <0xd>;
		ovp_reg = <0x36>;/* vbat ovp 4.85v */
		oplus_spec,voocphy_dual_cp_support;
		oplus_spec,slave_cp_enable_thr = <1400>;		//2000-100mA
		oplus_spec,slave_cp_disable_thr_high = <1100>;	//1500+100mA
		oplus_spec,voocphy_current_default = <73>;
		oplus_spec,ap_control_allow;

		oplus_spec,svooc_cool_down_current_limit = <146 20 20 24 30 34 40 44 50 54 60 64 70 74>;
		oplus_spec,vooc_cool_down_current_limit = <73 20 20 24 30 34 40 44 50 54 60 64 70 74>;

		oplus_spec,vooc_multistep_initial_batt_temp = <1000>;
		oplus_spec,vooc_little_cool_temp = <160>;
		oplus_spec,vooc_little_cool_high_temp = <210>;
		oplus_spec,vooc_cool_temp = <120>;
		oplus_spec,vooc_little_cold_temp = <50>;
		oplus_spec,vooc_normal_low_temp = <350>;
		oplus_spec,vooc_strategy_normal_current = <122>;
		oplus_spec,vooc_normal_to_little_cool_current = <100>;
		oplus_spec,vooc_over_high_temp = <510>;
		oplus_spec,vooc_low_temp = <0>;

		oplus_spec,vooc_high_temp = <500>;
		oplus_spec,vooc_low_soc = <0>;
		oplus_spec,vooc_high_soc = <95>;
		oplus_spec,vooc_normal_high_temp = <440>;
		oplus_spec,vooc_warm_vol_thr = <4000>;
		oplus_spec,vooc_warm_soc_thr = <50>;

		oplus_spec,vooc_strategy1_batt_high_temp0 = <385>;
		oplus_spec,vooc_strategy1_batt_high_temp1 = <395>;
		oplus_spec,vooc_strategy1_batt_high_temp2 = <420>;
		oplus_spec,vooc_strategy1_batt_low_temp2 = <410>;
		oplus_spec,vooc_strategy1_batt_low_temp1 = <385>;
		oplus_spec,vooc_strategy1_batt_low_temp0 = <375>;

		oplus_spec,vooc_strategy1_high_current0 = <80>;
		oplus_spec,vooc_strategy1_high_current1 = <61>;
		oplus_spec,vooc_strategy1_high_current2 = <40>;
		oplus_spec,vooc_strategy1_low_current2 = <40>;
		oplus_spec,vooc_strategy1_low_current1 = <61>;
		oplus_spec,vooc_strategy1_low_current0 = <80>;

		oplus_spec,voocphy_freq_mincore = <925000>;
		oplus_spec,voocphy_freq_midcore = <1718000>;
		oplus_spec,voocphy_freq_maxcore = <1718000>;
		oplus_spec,voocphy_current_change_timeout = <100>;
		oplus_spec,copycat_vooc_support;
		oplus_spec,copycat_vooc_accuracy_value = <105>;

		oplus_spec,fastchg_timeout_time_init = <145020>;
		oplus_spec,voocphy_ibat_over_current = <16000>;
		oplus_spec,voocphy_svooc_cp_max_ibus = <4500>;
		oplus_spec,voocphy_vooc_cp_max_ibus = <4500>;
		oplus_spec,voocphy_cp_max_ibus = <4500>;

		oplus_spec,vooc_little_cold_full_voltage = <4570>;
		oplus_spec,vooc_cool_full_voltage = <4570>;
		oplus_spec,vooc_little_cool_full_voltage = <4570>;
		oplus_spec,vooc_little_cool_high_full_voltage = <4570>;
		oplus_spec,vooc_warm_full_voltage = <4130>;
		oplus_spec,vooc_1time_full_voltage = <4580>;
		oplus_spec,vooc_ntime_full_voltage = <4570>;
		oplus_spec,soc_range = <0 20 35 55 75 85 95>;

		svooc_batt_sys_curve = <0 1 0 1 0 0 0	// 4000mA
					1 1 1 1 0 0 0	// 4604mV
					0 0 1 1 0 1 0	// 2600mA
					1 1 1 1 0 0 0	// 4604mV
					0 0 0 1 0 1 1	// 1100mA
					1 1 1 1 0 0 0>;	// 4604mV

		vooc_batt_sys_curve =  <0 1 0 1 0 0 0	// 4000mA
					1 1 1 1 0 0 0	// 4604mV
					0 0 1 1 0 1 0	// 2600mA
					1 1 1 1 0 0 0	// 4604mV
					0 0 0 1 0 1 1	// 1100mA
					1 1 1 1 0 0 0>;	// 4604mV

		svooc_lcf_strategy {
			oplus,temp_type = <OPLUS_STRATEGY_USE_SHELL_TEMP>;
			oplus,temp_range = <0 50 120 160 210 380 440>;

			strategy_temp_range_curves {
				strategy_temp_range_t0 =	<620 4570 0
								 595 4560 0
								 570 4550 0
								 545 4540 0
								 520 4530 1>;
				strategy_temp_range_t1 =	<1250 4570 0
								 1200 4565 0
								 1150 4550 0
								 1050 4540 0
								 950 4530 1>;
				strategy_temp_range_t2 =	<2150 4570 0
								 2100 4565 0
								 2000 4550 0
								 1900 4540 0
								 1750 4530 1>;
				strategy_temp_range_t3 =	<3200 4568 0
								 3000 4565 0
								 2400 4560 0
								 2000 4555 0
								 1500 4545 1>;
				strategy_temp_range_t4 =	<3200 4568 0
								 3000 4565 0
								 2400 4560 0
								 2000 4555 0
								 1500 4545 1>;
				strategy_temp_range_t5 =	<4100 4560 0
								 3700 4550 0
								 3000 4540 0
								 2400 4530 0
								 2000 4520 1>;
			};
		};

		svooc_charge_strategy {
			strategy_soc_0_to_50 { /* 0 ~ 20 */
				strategy_temp_little_cold =	<4150 25 0 0 0
								4280 20 0 0 0
								4560 15 0 0 0
								4570 10 1 0 0>;
				strategy_temp_cool =		<4150 35 0 0 0
								4150 30 0 0 0
								4280 25 0 0 0
								4560 20 0 0 0
								4560 15 0 0 0
								4570 10 1 0 0>;
				strategy_temp_little_cool =	<4150 61 0 840 0
								4150 50 0 0 0
								4510 47 0 0 0
								4510 45 0 0 0
								4510 40 0 0 0
								4560 39 0 0 0
								4560 35 0 0 0
								4560 30 0 0 0
								4560 25 0 0 0
								4560 20 0 0 0
								4560 15 0 0 0
								4570 11 1 0 0>;
				strategy_temp_little_cool_high =	<4180 73 0 0 0
								4280 62 0 0 0
								4280 50 0 0 0
								4510 49 0 0 0
								4510 40 0 0 0
								4560 36 0 0 0
								4560 35 0 0 0
								4560 30 0 0 0
								4560 25 0 0 0
								4560 20 0 0 0
								4565 18 0 0 0
								4565 15 0 0 0
								4560 10 1 0 0>;
				strategy_temp_normal_low =	<4180 73 0 100 0
								4280 62 0 240 0
								4280 50 0 0 0
								4510 49 0 0 0
								4510 40 0 0 0
								4560 36 0 0 0
								4560 35 0 0 0
								4560 30 0 0 0
								4560 25 0 0 0
								4560 20 0 0 0
								4565 18 0 0 0
								4565 15 0 0 0
								4560 10 1 0 0>;
				strategy_temp_normal_high =	<4180 73 0 100 0
								4280 62 0 240 0
								4280 50 0 0 0
								4510 49 0 0 0
								4510 40 0 0 0
								4560 36 0 0 0
								4560 35 0 0 0
								4560 30 0 0 0
								4560 25 0 0 0
								4565 22 0 0 0
								4550 15 0 0 0
								4530 10 1 0 0>;
				strategy_temp_warm =		<4120 15 0 0 0
								4130 10 1 0 0>;
			};

			strategy_soc_0_to_50_mid { /* 21 ~ 35 */
				strategy_temp_little_cold =	<4150 25 0 0 0
								4280 20 0 0 0
								4560 15 0 0 0
								4570 10 1 0 0>;
				strategy_temp_cool =		<4150 35 0 0 0
								4150 30 0 0 0
								4280 25 0 0 0
								4560 20 0 0 0
								4560 15 0 0 0
								4570 10 1 0 0>;
				strategy_temp_little_cool =	<4150 61 0 840 0
								4150 50 0 0 0
								4510 47 0 0 0
								4510 45 0 0 0
								4510 40 0 0 0
								4560 39 0 0 0
								4560 35 0 0 0
								4560 30 0 0 0
								4560 25 0 0 0
								4560 20 0 0 0
								4560 15 0 0 0
								4570 11 1 0 0>;
				strategy_temp_little_cool_high =	<4180 73 0 0 0
								4280 62 0 0 0
								4280 50 0 0 0
								4510 49 0 0 0
								4510 40 0 0 0
								4560 36 0 0 0
								4560 35 0 0 0
								4560 30 0 0 0
								4560 25 0 0 0
								4560 20 0 0 0
								4565 18 0 0 0
								4565 15 0 0 0
								4560 10 1 0 0>;
				strategy_temp_normal_low =	<4180 73 0 100 0
								4280 62 0 240 0
								4280 50 0 0 0
								4510 49 0 0 0
								4510 40 0 0 0
								4560 36 0 0 0
								4560 35 0 0 0
								4560 30 0 0 0
								4560 25 0 0 0
								4560 20 0 0 0
								4565 18 0 0 0
								4565 15 0 0 0
								4560 10 1 0 0>;
				strategy_temp_normal_high =	<4180 73 0 100 0
								4280 62 0 240 0
								4280 50 0 0 0
								4510 49 0 0 0
								4510 40 0 0 0
								4560 36 0 0 0
								4560 35 0 0 0
								4560 30 0 0 0
								4560 25 0 0 0
								4565 22 0 0 0
								4550 15 0 0 0
								4530 10 1 0 0>;
				strategy_temp_warm =		<4120 15 0 0 0
								4130 10 1 0 0>;
			};

			strategy_soc_0_to_50_high { /* 36 ~ 55 */
				strategy_temp_little_cold =	<4150 25 0 0 0
								4280 20 0 0 0
								4560 15 0 0 0
								4570 10 1 0 0>;
				strategy_temp_cool =		<4150 30 0 0 0
								4280 25 0 0 0
								4560 20 0 0 0
								4560 15 0 0 0
								4570 10 1 0 0>;
				strategy_temp_little_cool =	<4150 50 0 0 0
								4510 47 0 0 0
								4510 45 0 0 0
								4510 40 0 0 0
								4560 39 0 0 0
								4560 35 0 0 0
								4560 30 0 0 0
								4560 25 0 0 0
								4560 20 0 0 0
								4560 15 0 0 0
								4570 11 1 0 0>;
				strategy_temp_little_cool_high =	<4280 50 0 0 0
								4510 49 0 0 0
								4510 40 0 0 0
								4560 36 0 0 0
								4560 35 0 0 0
								4560 30 0 0 0
								4560 25 0 0 0
								4560 20 0 0 0
								4565 18 0 0 0
								4565 15 0 0 0
								4560 10 1 0 0>;
				strategy_temp_normal_low =	<4180 73 0 100 0
								4280 62 0 240 0
								4280 50 0 0 0
								4510 49 0 0 0
								4510 40 0 0 0
								4560 36 0 0 0
								4560 35 0 0 0
								4560 30 0 0 0
								4560 25 0 0 0
								4560 20 0 0 0
								4565 18 0 0 0
								4565 15 0 0 0
								4560 10 1 0 0>;
				strategy_temp_normal_high =	<4180 73 0 100 0
								4280 62 0 240 0
								4280 50 0 0 0
								4510 49 0 0 0
								4510 40 0 0 0
								4560 36 0 0 0
								4560 35 0 0 0
								4560 30 0 0 0
								4560 25 0 0 0
								4565 22 0 0 0
								4550 15 0 0 0
								4530 10 1 0 0>;
				strategy_temp_warm =		<4120 15 0 0 0
								4130 10 1 0 0>;
			};

			strategy_soc_50_to_75 { /* 56 ~ 75 */
				strategy_temp_little_cold =	<4280 20 0 0 0
								4560 15 0 0 0
								4570 10 1 0 0>;
				strategy_temp_cool =		<4280 25 0 0 0
								4560 20 0 0 0
								4560 15 0 0 0
								4570 10 1 0 0>;
				strategy_temp_little_cool =	<4560 30 0 0 0
								4560 25 0 0 0
								4560 20 0 0 0
								4560 15 0 0 0
								4570 11 1 0 0>;
				strategy_temp_little_cool_high =	<4560 30 0 0 0
								4560 25 0 0 0
								4560 20 0 0 0
								4565 18 0 0 0
								4565 15 0 0 0
								4560 10 1 0 0>;
				strategy_temp_normal_low =	<4560 35 0 0 0
								4560 30 0 0 0
								4560 25 0 0 0
								4560 20 0 0 0
								4565 18 0 0 0
								4565 15 0 0 0
								4560 10 1 0 0>;
				strategy_temp_normal_high =	<4510 40 0 0 0
								4560 36 0 0 0
								4560 35 0 0 0
								4560 30 0 0 0
								4560 25 0 0 0
								4565 22 0 0 0
								4550 15 0 0 0
								4530 10 1 0 0>;
				strategy_temp_warm =		<4120 15 0 0 0
								4130 10 1 0 0>;
			};

			strategy_soc_75_to_85 { /* 76 ~ 85 */
				strategy_temp_little_cold =	<4560 15 0 0 0
								4570 10 1 0 0>;
				strategy_temp_cool =		<4560 15 0 0 0
								4570 10 1 0 0>;
				strategy_temp_little_cool =	<4560 20 0 0 0
								4560 15 0 0 0
								4570 11 1 0 0>;
				strategy_temp_little_cool_high =	<4560 20 0 0 0
								4565 18 0 0 0
								4565 15 0 0 0
								4560 10 1 0 0>;
				strategy_temp_normal_low =	<4560 25 0 0 0
								4560 20 0 0 0
								4565 18 0 0 0
								4565 15 0 0 0
								4560 10 1 0 0>;
				strategy_temp_normal_high =	<4560 30 0 0 0
								4560 25 0 0 0
								4565 22 0 0 0
								4550 15 0 0 0
								4530 10 1 0 0>;
				strategy_temp_warm =		<4120 15 0 0 0
								4130 10 1 0 0>;
			};

			strategy_soc_85_to_90 { /* 86 ~ 95 */
				strategy_temp_little_cold =	<4570 10 1 0 0>;
				strategy_temp_cool =		<4570 10 1 0 0>;
				strategy_temp_little_cool =	<4570 11 1 0 0>;
				strategy_temp_little_cool_high = <4565 18 0 0 0
								4565 15 0 0 0
								4560 10 1 0 0>;
				strategy_temp_normal_low =	<4565 18 0 0 0
								4565 15 0 0 0
								4560 10 1 0 0>;
				strategy_temp_normal_high =	<4565 22 0 0 0
								4550 15 0 0 0
								4530 10 1 0 0>;
				strategy_temp_warm =		<4130 10 1 0 0>;
			};
		};

		vooc_charge_strategy {
			strategy_soc_0_to_50 {
				strategy_temp_little_cold =	<4150 50 0 0 0
								4280 40 0 0 0
								4560 30 0 0 0
								4570 20 1 0 0>;
				strategy_temp_cool =		<4150 60 0 0 0
								4280 50 0 0 0
								4560 40 0 0 0
								4560 30 0 0 0
								4570 20 1 0 0>;
				strategy_temp_little_cool =	<4560 60 0 0 0
								4560 50 0 0 0
								4560 40 0 0 0
								4560 30 0 0 0
								4570 22 1 0 0>;
				strategy_temp_little_cool_high =	<4560 60 0 0 0
								4560 50 0 0 0
								4560 40 0 0 0
								4565 36 0 0 0
								4565 30 0 0 0
								4560 20 1 0 0>;
				strategy_temp_normal_low =	<4560 60 0 0 0
								4560 50 0 0 0
								4560 40 0 0 0
								4565 36 0 0 0
								4565 30 0 0 0
								4560 20 1 0 0>;
				strategy_temp_normal_high =	<4560 60 0 0 0
								4560 50 0 0 0
								4565 44 0 0 0
								4550 30 0 0 0
								4530 20 1 0 0>;
				strategy_temp_warm =		<4120 30 0 0 0
								4130 20 1 0 0>;
			};

			strategy_soc_0_to_50_mid {
				strategy_temp_little_cold =	<4150 50 0 0 0
								4280 40 0 0 0
								4560 30 0 0 0
								4570 20 1 0 0>;
				strategy_temp_cool =		<4150 60 0 0 0
								4280 50 0 0 0
								4560 40 0 0 0
								4560 30 0 0 0
								4570 20 1 0 0>;
				strategy_temp_little_cool =	<4560 60 0 0 0
								4560 50 0 0 0
								4560 40 0 0 0
								4560 30 0 0 0
								4570 22 1 0 0>;
				strategy_temp_little_cool_high =	<4560 60 0 0 0
								4560 50 0 0 0
								4560 40 0 0 0
								4565 36 0 0 0
								4565 30 0 0 0
								4560 20 1 0 0>;
				strategy_temp_normal_low =	<4560 60 0 0 0
								4560 50 0 0 0
								4560 40 0 0 0
								4565 36 0 0 0
								4565 30 0 0 0
								4560 20 1 0 0>;
				strategy_temp_normal_high =	<4560 60 0 0 0
								4560 50 0 0 0
								4565 44 0 0 0
								4550 30 0 0 0
								4530 20 1 0 0>;
				strategy_temp_warm =		<4120 30 0 0 0
								4130 20 1 0 0>;
			};

			strategy_soc_0_to_50_high {
				strategy_temp_little_cold =	<4150 50 0 0 0
								4280 40 0 0 0
								4560 30 0 0 0
								4570 20 1 0 0>;
				strategy_temp_cool =		<4150 60 0 0 0
								4280 50 0 0 0
								4560 40 0 0 0
								4560 30 0 0 0
								4570 20 1 0 0>;
				strategy_temp_little_cool =	<4560 60 0 0 0
								4560 50 0 0 0
								4560 40 0 0 0
								4560 30 0 0 0
								4570 22 1 0 0>;
				strategy_temp_little_cool_high =	<4560 60 0 0 0
								4560 50 0 0 0
								4560 40 0 0 0
								4565 36 0 0 0
								4565 30 0 0 0
								4560 20 1 0 0>;
				strategy_temp_normal_low =	<4560 60 0 0 0
								4560 50 0 0 0
								4560 40 0 0 0
								4565 36 0 0 0
								4565 30 0 0 0
								4560 20 1 0 0>;
				strategy_temp_normal_high =	<4560 60 0 0 0
								4560 50 0 0 0
								4565 44 0 0 0
								4550 30 0 0 0
								4530 20 1 0 0>;
				strategy_temp_warm =		<4120 30 0 0 0
								4130 20 1 0 0>;
			};

			strategy_soc_50_to_75 {
				strategy_temp_little_cold =	<4280 40 0 0 0
								 4560 30 0 0 0
								 4570 20 1 0 0>;
				strategy_temp_cool =		<4280 50 0 0 0
								 4560 40 0 0 0
								 4560 30 0 0 0
								 4570 20 1 0 0>;
				strategy_temp_little_cool =	<4560 60 0 0 0
								 4560 50 0 0 0
								 4560 40 0 0 0
								 4560 30 0 0 0
								 4570 22 1 0 0>;
				strategy_temp_little_cool_high =	<4560 60 0 0 0
								 4560 50 0 0 0
								 4560 40 0 0 0
								 4565 36 0 0 0
								 4565 30 0 0 0
								 4560 20 1 0 0>;
				strategy_temp_normal_low =	<4560 60 0 0 0
								 4560 50 0 0 0
								 4560 40 0 0 0
								 4565 36 0 0 0
								 4565 30 0 0 0
								 4560 20 1 0 0>;
				strategy_temp_normal_high =	<4560 60 0 0 0
								 4560 50 0 0 0
								 4565 44 0 0 0
								 4550 30 0 0 0
								 4530 20 1 0 0>;
				strategy_temp_warm =		<4130 24 1 0 0>;
			};

			strategy_soc_75_to_85 {
				strategy_temp_little_cold =	<4560 30 0 0 0
								 4570 20 1 0 0>;
				strategy_temp_cool =		<4560 30 0 0 0
								 4570 20 1 0 0>;
				strategy_temp_little_cool =	<4560 40 0 0 0
								 4560 30 0 0 0
								 4570 22 1 0 0>;
				strategy_temp_little_cool_high = <4560 40 0 0 0
								 4565 36 0 0 0
								 4565 30 0 0 0
								 4560 20 1 0 0>;
				strategy_temp_normal_low =	<4560 50 0 0 0
								 4560 40 0 0 0
								 4565 36 0 0 0
								 4565 30 0 0 0
								 4560 20 1 0 0>;
				strategy_temp_normal_high =	<4560 60 0 0 0
								 4560 50 0 0 0
								 4565 46 0 0 0
								 4550 30 0 0 0
								 4530 20 1 0 0 >;
				strategy_temp_warm =		<4130 20 1 0 0>;
			};

			strategy_soc_85_to_90 {
				strategy_temp_little_cold =	<4570 20 1 0 0>;
				strategy_temp_cool =		<4570 20 1 0 0>;
				strategy_temp_little_cool =	<4570 22 1 0 0>;
				strategy_temp_little_cool_high = <4565 36 0 0 0
								 4565 30 0 0 0
								 4560 20 1 0 0>;
				strategy_temp_normal_low =	<4565 36 0 0 0
								 4565 30 0 0 0
								 4560 20 1 0 0>;
				strategy_temp_normal_high =	<4565 44 0 0 0
								 4550 30 0 0 0
								 4530 20 1 0 0>;
				strategy_temp_warm =		<4130 20 1 0 0>;
			};
		};
		oplus_sc8547_cp: oplus,sc8547_cp {
			oplus,ic_type = <OPLUS_CHG_IC_CP>;
			oplus,ic_index = <0>;
			oplus,ic_func_group = <&sc8547_cp_groups>;
		};
	};
};

&i2c13 {
	status = "okay";
	clock-frequency = <400000>;
	oplus_sc8547_slave: sc8547-charger-slave@6F{
		status = "okay";
		compatible = "slave_vphy_sc8547";
		reg = <0x6F>;
		pinctrl-names = "default";
		pinctrl-0 = <&i2c13_mode_default>;

		ocp_reg = <0xd>;
		ovp_reg = <0x36>;/* vbat ovp 4.85v */
		oplus_sc8547_slave_cp: oplus,sc8547_slave_cp {
			oplus,ic_type = <OPLUS_CHG_IC_CP>;
			oplus,ic_index = <1>;
			oplus,ic_func_group = <&sc8547_cp_groups>;
		};
	};
};

&pio {
	i2c13_mode_default: i2c13_mode_default {
		pins_cmd_dat {
			pinmux = <PINMUX_GPIO163__FUNC_SCL13>,
				<PINMUX_GPIO164__FUNC_SDA13>;
			bias-pull-up = <MTK_PULL_SET_RSEL_111>;
		};
	};
};

//for ufcs config
&soc {
	oplus_ufcs_impedance_check: oplus,ufcs_impedance_check {
		compatible = "oplus,impedance_check";

		oplus,impedance_unit {
			oplus_ufcs_impedance_unit: oplus,ufcs_impedance_unit {
				uint_name = "ufcs";
				default_curr_ma = <3000>;
				impedance_node = <&ufcs_input_impedance>;
			};
		};
	};
};

&soc {
	oplus_cpa: oplus,cpa {
		compatible = "oplus,cpa";
		oplus,protocol_list = <CHG_PROTOCOL_UFCS 33
				       CHG_PROTOCOL_PD 18
				       CHG_PROTOCOL_VOOC 80
				       CHG_PROTOCOL_QC 18>;
		oplus,default_protocol_list = <CHG_PROTOCOL_UFCS
					       CHG_PROTOCOL_PD
					       CHG_PROTOCOL_VOOC>;
	};

	oplus_ufcs_virtual_cp: oplus,ufcs_virtual_cp {
		compatible = "oplus,virtual_cp";

		oplus,ic_type = <OPLUS_CHG_IC_VIRTUAL_CP>;
		oplus,ic_index = <1>;

		oplus,cp_ic = <&oplus_virtual_cp>;
		oplus,input_curr_max_ma = <9100>;

		oplus,cp_ic_connect = <OPLUS_CHG_IC_CONNECT_PARALLEL>;
		oplus,main_cp = <0>;
	};

	oplus_virtual_ufcs: oplus,virtual_ufcs {
		compatible = "oplus,virtual_ufcs";

		oplus,ic_type = <OPLUS_CHG_IC_VIRTUAL_UFCS>;
		oplus,ic_index = <0>;
	};

	oplus_ufcs_charge: oplus,ufcs_charge {
		compatible = "oplus,ufcs_charge";
		oplus,ufcs_ic = <&oplus_virtual_ufcs>;
		oplus,cp_ic = <&oplus_virtual_cp>;
		oplus,dpdm_switch_ic = <&oplus_virtual_dpdm_switch>;

		oplus,impedance_unit = <&oplus_ufcs_impedance_unit>;

		oplus,target_vbus_mv = <11000>;
		oplus,curr_max_ma = <3000>;

		oplus,curr_table_type = <UFCS_CURR_CP_TABLE>;
		oplus,high_imp_compensation_setting_mv = <50>;

		oplus,ufcs_warm_allow_vol = <4000>;
		oplus,ufcs_warm_allow_soc = <50>;
		oplus,ufcs_strategy_normal_current = <3000>;
		oplus,ufcs_over_high_or_low_current = <3000>;
		oplus,ufcs_timeout_third = <10800>;
		oplus,ufcs_timeout_oplus = <10800>;
		oplus,ufcs_ibat_over_third = <7000>;
		oplus,ufcs_ibat_over_oplus = <7000>;
		oplus,ufcs_full_cool_sw_vbat = <4490>;
		oplus,ufcs_full_normal_sw_vbat = <4490>;
		oplus,ufcs_full_normal_hw_vbat = <4500>;
		oplus,ufcs_full_ffc_vbat = <4520>;
		oplus,ufcs_full_warm_vbat = <4130>;
		oplus,ufcs_full_cool_sw_vbat_third = <4490>;
		oplus,ufcs_full_normal_sw_vbat_third= <4490>;
		oplus,ufcs_full_normal_hw_vbat_third = <4500>;
		oplus,ufcs_current_change_timeout = <100>;
		oplus,ufcs_strategy_batt_high_temp = <410 420 430 400 410 420>;
		oplus,ufcs_strategy_high_current = <3000 2000 2000 3000 3000 3000>;
		oplus,ufcs_little_cool_high_temp = <210>;
		oplus,curve_strategy_name = "pps_ufcs_curve_v2";
		oplus_spec,ufcs_high_soc = <95>;
		oplus,ufcs_charge_strategy_soc = <0 20 35 50 75 85 95>;
		oplus,ufcs_charge_strategy_temp = <0 50 120 160 350 440 530>;

		oplus,plc_strategy-data = <&oplus_ufcs_step_strategy &third_ufcs_simple_strategy>;
		oplus,plc_strategy-names = "default", "third";

		ufcs_oplus_lcf_strategy {
			oplus,temp_type = <OPLUS_STRATEGY_USE_SHELL_TEMP>;
			oplus,temp_range = <0 50 120 160 210 380 440>;

			strategy_temp_range_curves {
				strategy_temp_range_t0 =	<620 4570 0
								 595 4560 0
								 570 4550 0
								 545 4540 0
								 520 4530 1>;
				strategy_temp_range_t1 =	<1250 4570 0
								 1200 4565 0
								 1150 4550 0
								 1050 4540 0
								 950 4530 1>;
				strategy_temp_range_t2 =	<2150 4570 0
								 2100 4565 0
								 2000 4550 0
								 1900 4540 0
								 1750 4530 1>;
				strategy_temp_range_t3 =	<3400 4570 0
								 3350 4565 0
								 3250 4550 0
								 3150 4540 0
								 3000 4530 1>;
				strategy_temp_range_t4 =	<3400 4570 0
								 3350 4565 0
								 3250 4550 0
								 3150 4540 0
								 3000 4530 1>;
				strategy_temp_range_t5 =	<4300 4570 0
								 4250 4565 0
								 4150 4550 0
								 4050 4540 0
								 3900 4530 1>;
			};
		};

		ufcs_third_lcf_strategy {
			oplus,temp_type = <OPLUS_STRATEGY_USE_SHELL_TEMP>;
			oplus,temp_range = <0 50 120 160 210 380 440>;

			strategy_temp_range_curves {
				strategy_temp_range_t0 =	<620 4570 0
								 595 4560 0
								 570 4550 0
								 545 4540 0
								 520 4530 1>;
				strategy_temp_range_t1 =	<1250 4570 0
								 1200 4565 0
								 1150 4550 0
								 1050 4540 0
								 950 4530 1>;
				strategy_temp_range_t2 =	<2150 4570 0
								 2100 4565 0
								 2000 4550 0
								 1900 4540 0
								 1750 4530 1>;
				strategy_temp_range_t3 =	<3400 4570 0
								 3350 4565 0
								 3250 4550 0
								 3150 4540 0
								 3000 4530 1>;
				strategy_temp_range_t4 =	<3400 4570 0
								 3350 4565 0
								 3250 4550 0
								 3150 4540 0
								 3000 4530 1>;
				strategy_temp_range_t5 =	<4300 4570 0
								 4250 4565 0
								 4150 4550 0
								 4050 4540 0
								 3900 4530 1>;
			};
		};

		ufcs_charge_third_strategy {
			oplus,temp_type = <OPLUS_STRATEGY_USE_SHELL_TEMP>;
			oplus,soc_range = <0 20 35 55 75 85 95>;
			oplus,temp_range = <0 50 120 160 210 350 440 510>;

			strategy_soc_range_min {
				strategy_temp_little_cold =	<11000 4150 2500 0 0
								11000 4280 2000 0 0
								11000 4480 1500 0 0
								11000 4490 1000 1 0>;
				strategy_temp_cool =		<11000 4150 3000 0 0
								11000 4280 2500 0 0
								11000 4480 2000 0 0
								11000 4480 1500 0 0
								11000 4490 1000 1 0>;
				strategy_temp_little_cool =	<11000 4480 3000 0 0
								11000 4480 2500 0 0
								11000 4480 2000 0 0
								11000 4480 1500 0 0
								11000 4490 1000 1 0>;
				strategy_temp_little_cool_high =	<11000 4480 3000 0 0
								11000 4480 2500 0 0
								11000 4480 2000 0 0
								11000 4480 1500 0 0
								11000 4490 1000 1 0>;
				strategy_temp_normal_low =	<11000 4480 3000 0 0
								11000 4480 2500 0 0
								11000 4480 2000 0 0
								11000 4480 1500 0 0
								11000 4490 1000 1 0>;
				strategy_temp_normal_high =	<11000 4460 3000 0 0
								11000 4460 2500 0 0
								11000 4460 2000 0 0
								11000 4460 1500 0 0
								11000 4470 1000 1 0>;
				strategy_temp_warm =		<11000 4120 1550 0 0
								11000 4120 1500 0 0
								11000 4130 1000 1 0>;
			};
			strategy_soc_range_low {
				strategy_temp_little_cold =	<11000 4150 2500 0 0
								11000 4280 2000 0 0
								11000 4480 1500 0 0
								11000 4490 1000 1 0>;
				strategy_temp_cool =		<11000 4150 3000 0 0
								11000 4280 2500 0 0
								11000 4480 2000 0 0
								11000 4480 1500 0 0
								11000 4490 1000 1 0>;
				strategy_temp_little_cool =	<11000 4480 3000 0 0
								11000 4480 2500 0 0
								11000 4480 2000 0 0
								11000 4480 1500 0 0
								11000 4490 1000 1 0>;
				strategy_temp_little_cool_high =	<11000 4480 3000 0 0
								11000 4480 2500 0 0
								11000 4480 2000 0 0
								11000 4480 1500 0 0
								11000 4490 1000 1 0>;
				strategy_temp_normal_low =	<11000 4480 3000 0 0
								11000 4480 2500 0 0
								11000 4480 2000 0 0
								11000 4480 1500 0 0
								11000 4490 1000 1 0>;
				strategy_temp_normal_high =	<11000 4460 3000 0 0
								11000 4460 2500 0 0
								11000 4460 2000 0 0
								11000 4460 1500 0 0
								11000 4470 1000 1 0>;
				strategy_temp_warm =		<11000 4120 1500 0 0
								11000 4130 1000 1 0>;
			};
			strategy_soc_range_mid_low {
				strategy_temp_little_cold =	<11000 4150 2500 0 0
								11000 4280 2000 0 0
								11000 4480 1500 0 0
								11000 4490 1000 1 0>;
				strategy_temp_cool =		<11000 4150 3000 0 0
								11000 4280 2500 0 0
								11000 4480 2000 0 0
								11000 4480 1500 0 0
								11000 4490 1000 1 0>;
				strategy_temp_little_cool =	<11000 4480 3000 0 0
								11000 4480 2500 0 0
								11000 4480 2000 0 0
								11000 4480 1500 0 0
								11000 4490 1000 1 0>;
				strategy_temp_little_cool_high =	<11000 4480 3000 0 0
								11000 4480 2500 0 0
								11000 4480 2000 0 0
								11000 4480 1500 0 0
								11000 4490 1000 1 0>;
				strategy_temp_normal_low =	<11000 4480 3000 0 0
								11000 4480 2500 0 0
								11000 4480 2000 0 0
								11000 4480 1500 0 0
								11000 4490 1000 1 0>;
				strategy_temp_normal_high =	<11000 4460 3000 0 0
								11000 4460 2500 0 0
								11000 4460 2000 0 0
								11000 4460 1500 0 0
								11000 4470 1000 1 0>;
				strategy_temp_warm =		<11000 4120 1500 0 0
								11000 4130 1000 1 0>;
			};
			strategy_soc_range_mid {
				strategy_temp_little_cold =	<11000 4480 1500 0 0
								11000 4490 1000 1 0>;
				strategy_temp_cool =		<11000 4480 1500 0 0
								11000 4490 1000 1 0>;
				strategy_temp_little_cool =	<11000 4480 2000 0 0
								11000 4480 1500 0 0
								11000 4490 1000 1 0>;
				strategy_temp_little_cool_high =	<11000 4480 2000 0 0
								11000 4480 1500 0 0
								11000 4490 1000 1 0>;
				strategy_temp_normal_low =	<11000 4480 2500 0 0
								11000 4480 2000 0 0
								11000 4480 1500 0 0
								11000 4490 1000 1 0>;
				strategy_temp_normal_high =	<11000 4460 3000 0 0
								11000 4460 2500 0 0
								11000 4460 2000 0 0
								11000 4460 1500 0 0
								11000 4470 1000 1 0>;
				strategy_temp_warm =		<11000 4120 1500 0 0
								11000 4130 1000 1 0>;
			};
			strategy_soc_range_mid_high {
				strategy_temp_little_cold =	<11000 4490 1000 1 0>;
				strategy_temp_cool =		<11000 4490 1000 1 0>;
				strategy_temp_little_cool =	<11000 4480 1500 0 0
								11000 4490 1000 1 0>;
				strategy_temp_little_cool_high =	<11000 4480 1500 0 0
								11000 4490 1000 1 0>;
				strategy_temp_normal_low =	<11000 4480 2000 0 0
								11000 4480 1500 0 0
								11000 4490 1000 1 0>;
				strategy_temp_normal_high =	<11000 4460 2500 0 0
								11000 4460 2000 0 0
								11000 4460 1500 0 0
								11000 4470 1000 1 0>;
				strategy_temp_warm =		<11000 4120 1500 0 0
								11000 4130 1000 1 0>;
			};
			strategy_soc_range_high {
				strategy_temp_little_cold =	<11000 4490 1000 1 0>;
				strategy_temp_cool =		<11000 4490 1000 1 0>;
				strategy_temp_little_cool =	<11000 4490 1000 1 0>;
				strategy_temp_little_cool_high =	<11000 4490 1000 1 0>;
				strategy_temp_normal_low =	<11000 4490 1000 1 0>;
				strategy_temp_normal_high =	<11000 4460 1500 0 0
								 11000 4470 1000 1 0>;
				strategy_temp_warm =		<11000 4130 1000 1 0>;
			};
		};

		ufcs_charge_oplus_strategy {
			oplus,temp_type = <OPLUS_STRATEGY_USE_SHELL_TEMP>;
			oplus,soc_range = <0 20 35 55 75 85 95>;
			oplus,temp_range = <0 50 120 160 210 350 440 510>;

			strategy_soc_range_min {
				strategy_temp_little_cold =	<11000 4150 3000 0 0
								11000 4480 2600 0 0
								11000 4480 2500 0 0
								11000 4480 2000 0 0
								11000 4480 1500 0 0
								11000 4490 1000 1 0>;
				strategy_temp_cool =		<11000 4480 3000 0 0
								11000 4480 2500 0 0
								11000 4480 2000 0 0
								11000 4480 1500 0 0
								11000 4490 1000 1 0>;
				strategy_temp_little_cool =	<11000 4480 3000 0 0
								11000 4480 2500 0 0
								11000 4480 2000 0 0
								11000 4480 1500 0 0
								11000 4490 1000 1 0>;
				strategy_temp_little_cool_high =	<11000 4480 3000 0 0
								11000 4480 2500 0 0
								11000 4480 2000 0 0
								11000 4480 1500 0 0
								11000 4490 1000 1 0>;
				strategy_temp_normal_low =	<11000 4480 3000 0 0
								11000 4480 2500 0 0
								11000 4480 2000 0 0
								11000 4480 1500 0 0
								11000 4490 1000 1 0>;
				strategy_temp_normal_high =	<11000 4460 3000 0 0
								11000 4460 2500 0 0
								11000 4460 2000 0 0
								11000 4460 1500 0 0
								11000 4470 1000 1 0>;
				strategy_temp_warm =		<11000 4120 1550 0 0
								11000 4120 1500 0 0
								11000 4130 1000 1 0>;
			};
			strategy_soc_range_low {
				strategy_temp_little_cold =	<11000 4150 3000 0 0
								11000 4480 2600 0 0
								11000 4480 2500 0 0
								11000 4480 2000 0 0
								11000 4480 1500 0 0
								11000 4490 1000 1 0>;
				strategy_temp_cool =		<11000 4480 3000 0 0
								11000 4480 2500 0 0
								11000 4480 2000 0 0
								11000 4480 1500 0 0
								11000 4490 1000 1 0>;
				strategy_temp_little_cool =	<11000 4480 3000 0 0
								11000 4480 2500 0 0
								11000 4480 2000 0 0
								11000 4480 1500 0 0
								11000 4490 1000 1 0>;
				strategy_temp_little_cool_high =	<11000 4480 3000 0 0
								11000 4480 2500 0 0
								11000 4480 2000 0 0
								11000 4480 1500 0 0
								11000 4490 1000 1 0>;
				strategy_temp_normal_low =	<11000 4500 3000 0 0
								11000 4480 2500 0 0
								11000 4480 2000 0 0
								11000 4480 1500 0 0
								11000 4490 1000 1 0>;
				strategy_temp_normal_high =	<11000 4460 3000 0 0
								11000 4460 2500 0 0
								11000 4460 2000 0 0
								11000 4460 1500 0 0
								11000 4470 1000 1 0>;
				strategy_temp_warm =		<11000 4120 1500 0 0
								11000 4130 1000 1 0>;
			};
			strategy_soc_range_mid_low {
				strategy_temp_little_cold =	<11000 4480 2500 0 0
								11000 4480 2000 0 0
								11000 4480 1500 0 0
								11000 4490 1000 1 0>;
				strategy_temp_cool =		<11000 4480 3000 0 0
								11000 4480 2500 0 0
								11000 4480 2000 0 0
								11000 4480 1500 0 0
								11000 4490 1000 1 0>;
				strategy_temp_little_cool =	<11000 4480 3000 0 0
								11000 4480 2500 0 0
								11000 4480 2000 0 0
								11000 4480 1500 0 0
								11000 4490 1000 1 0>;
				strategy_temp_little_cool_high =	<11000 4480 3000 0 0
								11000 4480 2500 0 0
								11000 4480 2000 0 0
								11000 4480 1500 0 0
								11000 4490 1000 1 0>;
				strategy_temp_normal_low =	<11000 4480 3000 0 0
								11000 4480 2500 0 0
								11000 4480 2000 0 0
								11000 4480 1500 0 0
								11000 4490 1000 1 0>;
				strategy_temp_normal_high =	<11000 4460 3000 0 0
								11000 4460 2500 0 0
								11000 4460 2000 0 0
								11000 4460 1500 0 0
								11000 4470 1000 1 0>;
				strategy_temp_warm =		<11000 4120 1500 0 0
								11000 4130 1000 1 0>;
			};
			strategy_soc_range_mid {
				strategy_temp_little_cold =	<11000 4480 1500 0 0
								11000 4490 1000 1 0>;
				strategy_temp_cool =		<11000 4480 1500 0 0
								11000 4490 1000 1 0>;
				strategy_temp_little_cool =	<11000 4480 2000 0 0
								11000 4480 1500 0 0
								11000 4490 1000 1 0>;
				strategy_temp_little_cool_high =	<11000 4480 2000 0 0
								11000 4480 1500 0 0
								11000 4490 1000 1 0>;
				strategy_temp_normal_low =	<11000 4480 2500 0 0
								11000 4480 2000 0 0
								11000 4480 1500 0 0
								11000 4490 1000 1 0>;
				strategy_temp_normal_high =	<11000 4460 3000 0 0
								11000 4460 2500 0 0
								11000 4460 2000 0 0
								11000 4460 1500 0 0
								11000 4470 1000 1 0>;
				strategy_temp_warm =		<11000 4120 1500 0 0
								11000 4130 1000 1 0>;
			};
			strategy_soc_range_mid_high {
				strategy_temp_little_cold =	<11000 4490 1000 1 0>;
				strategy_temp_cool =		<11000 4490 1000 1 0>;
				strategy_temp_little_cool =	<11000 4480 1500 0 0
								11000 4490 1000 1 0>;
				strategy_temp_little_cool_high =	<11000 4480 1500 0 0
								11000 4490 1000 1 0>;
				strategy_temp_normal_low =	<11000 4480 2000 0 0
								11000 4480 1500 0 0
								11000 4490 1000 1 0>;
				strategy_temp_normal_high =	<11000 4460 2500 0 0
								11000 4460 2000 0 0
								11000 4460 1500 0 0
								11000 4470 1000 1 0>;
				strategy_temp_warm =		<11000 4120 1500 0 0
								11000 4130 1000 1 0>;
			};
			strategy_soc_range_high {
				strategy_temp_little_cold =	<11000 4490 1000 1 0>;
				strategy_temp_cool =		<11000 4490 1000 1 0>;
				strategy_temp_little_cool =	<11000 4490 1000 1 0>;
				strategy_temp_little_cool_high =	<11000 4490 1000 1 0>;
				strategy_temp_normal_low =	<11000 4490 1000 1 0>;
				strategy_temp_normal_high =	<11000 4460 1500 0 0
								 11000 4470 1000 1 0>;
				strategy_temp_warm =		<11000 4130 1000 1 0>;
			};
		};
		oplus,impedance_node {
			ufcs_input_impedance: ufcs_input_impedance {
				node_name = "ufcs_input";
				default_impedance_mohm = <0>;
				default_curr_ma = <3000>;
				current_drop_table = <
					250  4000
					340  3000
					380  2000
					480 0
				>;
			};
		};
	};
};

#include "oplus-chg-24021-pps.dtsi"

/* chagrge end */

//#ifdef OPLUS_FEATURE_CHG_BASIC /* BSP.CHG.Basic, 2023/10/30, sjc Add for wls charging */
&charger {
	oplus,wls_boost_vol_start_mv = <5500>;
	oplus,wls_boost_vol_max_mv = <5500>;
	oplus,low_batt_otg_boost_curr_ua = <500000>;
};

&soc {
	oplus_chg_wls: oplus,chg_wls {
		status = "ok";
		compatible = "oplus,chg_wls";

		oplus,rx_ic = <&oplus_virtual_rx>;
		oplus,nor_ic = <&oplus_virtual_buck>;
		oplus,fast_ic = <&oplus_virtual_cp>;

		oplus,support_fastchg;
		oplus,support_epp_plus;
		//oplus,support_wls_chg_bcc;
		oplus,support_acdrv_no_ext_boost;

		oplus,max-voltage-mv = <4570>;
		oplus,fastchg_curr_max_ma = <5000>;
		oplus,verity_curr_max_ma = <5000>;
		oplus,wls-fast-chg-call-on-curr-ma = <600>;
		oplus,wls-fast-chg-camera-on-curr-ma = <600>;
		oplus,wls_power_mw = <50000>;
		oplus,wls_phone_id = <0x16>;
		oplus,wls-bcc-fcc-to-icl-factor = <2>;
		oplus,little_warm_batt_temp = <200>;
		oplus,wls_boost_curr_limit_ma = <1500>;
		oplus,rx_protocol_version = <30>;
		oplus,rx_coil = <48>;
		oplus,vbridge_ratio = <14>;
		oplus,magcvr_vbridge_ratio = <28>;
		oplus,non_mag_power_mw = <20000>;
		/*
		 * | temp_min | temp_max | target_curr_ma(mA) |
		 *
		 * temp_min: Switch to the previous level when the temperature is lower
		 *           than this value. If it is 0, do not switch.
		 * temp_max: Switch to the next level when the temperature is greater
		 *           than this value
		 */
		oplus,epp_plus-skin-step = <0 360 1700
					    350 380 1700
					    360 390 1700
					    370 410 1700>;
		oplus,epp-skin-step = <0 390 1500
				       360 400 1500>;
		oplus,bpp-skin-step = <0 390 750
				       370 400 750>;
		oplus,epp_plus-led-on-skin-step = <0 390 1700
						   380 500 1700>;
		oplus,epp-led-on-skin-step = <0 390 1500
					      380 500 1500>;

		/*
		 * | cool_temp | heat_temp | curr_data | heat_next_index | cool_next_index |
		 */
		oplus,wls-fast-chg-led-off-strategy-data = <0 410 5000 1 0
							    390 450 2400 1 0>;
		oplus,wls-fast-chg-led-on-strategy-data = <0 340 5000 1 0
							   330 360 2000 2 0
							   350 380 1600 3 1
							   370 400 1200 3 2>;

		oplus,iclmax-ma = <300 750 750 750 750 750 750 750 300    /*wls-bpp(mA)*/
				   600 800 1500 1500 1500 1500 1500 800 600    /*wls-epp(mA)*/
				   600 800 1700 1700 1700 1700 1700 800 600    /*wls-epp-plus(mA)*/
				   600 750 2000 2000 2000 2000 2000 750 600    /*wls-airvooc(mA)*/
				   600 800 2000 2500 5000 5000 5000 800 600>;  /*wls-airsvooc(mA)*/
		oplus,iclmax-batt-high-ma = <300 400 750 750 750 750 750 750 300    /*wls-bpp(mA)*/
					     600 500 800 1500 1500 1500 1500 800 600    /*wls-epp(mA)*/
					     600 500 800 1700 1700 1700 1700 800 600    /*wls-epp-plus(mA)*/
					     600 400 750 2000 2000 2000 2000 750 600    /*wls-airvooc(mA)*/
					     600 400 2000 2500 5000 5000 5000 800 600>;  /*wls-airsvooc(mA)*/

		/*
		 * | temp_min | temp_max | target_curr_ma | vol_max_mv | need wait |
		 * temp_min/temp_max: not use here
		 * target_curr_ma: wls icl when vbat < vol_max_mv
		 * vol_max_mv: the last value is always 5000mV(must be greater than the max-vbat)
		 * need wait: not use here
		 */
		non-ffc-bpp =		<0 0 750  5000 0>;
		non-ffc-epp =		<0 0 1500  4385 0
					0 0 800  5000 0>;
		non-ffc-epp-plus =	<0 0 1700 4380 0
					0 0 1500  4385 0
					0 0 800  5000 0>;
		non-ffc-airvooc =	<0 0 1800  4375 0
					0 0 800  5000 0>;
		non-ffc-airsvooc =	<0 0 2000  4380 0
					0 0 750  5000 0>;
		/*
		 * | temp_min | temp_max | target_curr_ma | vol_max_mv | need wait |
		 * temp_min: Switch to the previous level when the temperature is lower
		 *           than this value. If it is 0, do not switch.
		 * temp_max: Switch to the next level when the temperature is higher
		 *           than this value
		 * target_curr_ma: wls icl when vbat > vol_max_mv
		 * vol_max_mv: Maximum battery voltage.
		 * need wait: not use here
		 */
		cv-bpp = 	<(-100) 350 500 4490 0
				350 450 400 4470 0
				450 530 400 4130 0>;
		cv-epp =	<(-100) 0 600 4490 0
				0 350 600 4490 0
				350 450 600 4470 0
				450 530 600 4130 0>;
		cv-epp-plus =	<(-100) 0 600 4490 0
				0 350 600 4490 0
				350 450 600 4470 0
				450 530 600 4130 0>;
		cv-airvooc =	<(-100) 0 600 4490 0
				0 350 600 4490 0
				350 450 600 4470 0
				450 530 600 4130 0>;
		cv-airsvooc =	<(-100) 0 600 4490 0
				0 350 600 4490 0
				350 450 600 4470 0
				450 530 600 4130 0>;

		cv-bpp-high-batt = 	<(-100) 350 400 4490 0
				350 450 400 4470 0
				450 530 400 4130 0>;
		cv-epp-high-batt =	<(-100) 0 300 4490 0
				0 350 600 4490 0
				350 450 600 4470 0
				450 530 600 4130 0>;
		cv-epp-plus-high-batt =	<(-100) 0 300 4490 0
				0 350 600 4490 0
				350 450 600 4470 0
				450 530 600 4130 0>;
		cv-airvooc-high-batt =	<(-100) 0 300 4490 0
				0 350 600 4490 0
				350 450 600 4470 0
				450 530 600 4130 0>;
		cv-airsvooc-high-batt =	<(-100) 0 300 4490 0
				0 350 600 4490 0
				350 450 600 4470 0
				450 530 600 4130 0>;

		oplus,cool-down-12v-thr = <2>;//switch to 5.5V level
		cool-down-bpp = <0 750 750 750 750 750 750>;
		cool-down-epp = <0 800 800 1500 1500 1500 1500>;
		cool-down-epp-plus = <0 800 800 1500 1500 1500 1700>;
		cool-down-airvooc = <0 800 800 2000 2000 2000 2000>;
		cool-down-airsvooc = <0 800 1100 1200 1500 1700 2000 2200 2500 2500 2500 2500 2500>;

		/*
		 * | bcc_stop_curr |
		 * The three parameters of each array
		 * correspond to three temperature intervals: 0-5; 5-12; 12-44
		 */
		bcc_stop_curr_0_to_30 = <1000 1000 1300 1300 1300>;
		bcc_stop_curr_30_to_70 = <1000 1000 1300 1300 1300>;
		bcc_stop_curr_70_to_90 = <1000 1000 1300 1300 1300>;

		/*
		 * | curr_ma | fallback_step | switch_to_bpp
		 * curr_ma: wls icl in this step
		 * fallback_step: 0: don't fallback when CEP is OK
		 *                1/2...: fallback to 1st/2nd step when CEP is OK
		 * switch_to_bpp: reach the final step, switch to bpp when CEP is not OK
		 */
		skewing-epp =		<1500 0 0
					1200 0 0
					800 1 0>;
		skewing-epp-plus =	<1700 0 0
					1600 0 0
					1200 2 0
					800 3 0>;//fallback to 800(2nd step) when CEP is OK at this step
		skewing-airvooc =	<2000 0 0
					800 0 0>;

		/* fod parameter*/
		/*
		 * oplus,fastchg-match-q: | wls_base(dock) id | q value | f value
		 * oplus,fod-parm-array-row-len: dock id len(1) + oplus,fastchg-fod-parm-len, only for new projects
		 *                               old projects: WLS_FOD_PARM_LEN_MAX is 32
		 *                               new projects: WLS_FOD_PARM_LEN_MAX is 64
		 * oplus,fastchg-fod-parm-len: fod parm length, DO NOT include wls_base(dock) id
		 * oplus,fastchg-fod-parm: | wls_base(dock) id | WLS_FOD_PARM_LEN_MAX(32) pieces of fod parms |
		 *                         default wls_base id is 0xff
		 * oplus,disable-fod-parm: disable fod parm, DO NOT include wls_base(dock) id
		 */
		oplus,fastchg-fod-enable;
		oplus,fastchg-match-q = /bits/ 8 <0x00 0x41 0x55
						0x01 0x41 0x55
						0x02 0x46 0x55
						0x03 0x58 0x55
						0x04 0x08 0x5F
						0x1f 0x46 0x55>;
		oplus,fastchg-match-q-magcvr = /bits/ 8 <0x00 0x30 0x55
						0x01 0x30 0x55
						0x02 0x2C 0x55
						0x03 0x26 0x55
						0x04 0x08 0x5F
						0x1f 0x30 0x55>;
		oplus,fod-parm-array-row-len = <41>;
		oplus,fastchg-fod-parm-len = <40>;
		/*oplus,fastchg-fod-parm = /bits/ 8 <0xff  0xff 0x7f 0xff 0x7f 0xa1 0x10 0x9e 0x7f 0xae 0x00 0xa8 0x7f 0xa7 0x40
							 0xff 0xff 0xff 0xff 0xff 0xff 0xff 0xff 0xff 0xff 0xff 0xff 0xff 0xff 0xff 0xff 0xff 0xff>;*/
		/*wls_base(dock) id | fod parms*/
		oplus,fastchg-fod-parm =	/bits/ 8 <0x04  0x80 0x19 0x80 0x0E 0x6C 0x0A 0x6A 0x1C 0x6A 0x26 0x68 0x17 0x68 0x16 0x64 0x15 0x64 0x19 0x60 0x0E
								0x60 0x0A 0x5E 0x0E 0x54 0x0D 0x48 0x0E 0x48 0x0C 0x46 0x0E 0x41 0x0E 0x3F 0x0D 0x3F 0x0C 0x3C 0x0D
							  0x1f  0x60 0x35 0x38 0x30 0x30 0x28 0x2D 0x1E 0x2D 0x28 0x2C 0x28 0x2C 0x28 0x2A 0x1E 0x2A 0x1E 0x29 0x1E
								0x27 0x20 0x26 0x21 0x26 0x21 0x26 0x20 0x26 0x22 0x23 0x26 0x23 0x27 0x22 0x28 0x21 0x28 0x20 0x1A
							  0xff  0x60 0x17 0x38 0x12 0x30 0x0A 0x2D 0x0A 0x2D 0x0A 0x2C 0x0A 0x2C 0x0A 0x2A 0x0A 0x2A 0x0A 0x29 0x0A
								0x27 0x0C 0x26 0x0D 0x26 0x0D 0x26 0x0C 0x26 0x0E 0x23 0x12 0x23 0x13 0x22 0x14 0x21 0x14 0x20 0x06>;
		oplus,fastchg-fod-parm-magcvr = /bits/ 8 <0x04  0x80 0x46 0x80 0x41 0x80 0x3A 0x80 0x38 0x80 0x26 0x60 0x3C 0x5D 0x1C 0x5A 0x2A 0x56 0x37 0x53 0x22
								0x4C 0x22 0x40 0x28 0x3E 0x22 0x3A 0x23 0x36 0x23 0x35 0x25 0x35 0x1C 0x35 0x18 0x34 0x0A 0x32 0x0B
							  0x1f  0x60 0x2F 0x38 0x3A 0x30 0x42 0x2D 0x42 0x2D 0x3C 0x2C 0x3C 0x2C 0x3C 0x2A 0x3C 0x2A 0x3C 0x29 0x3C
								0x27 0x34 0x26 0x35 0x26 0x35 0x26 0x34 0x26 0x36 0x23 0x3A 0x23 0x3B 0x22 0x3C 0x21 0x3C 0x20 0x2E
							  0xff  0x64 0x28 0x5A 0x1E 0x5A 0x05 0x4B 0x02 0x46 0x03 0x3C 0x0F 0x3C 0x10 0x3C 0x10 0x3C 0x07 0x3C 0x05
								0x3C 0x01 0x37 0x04 0x37 0x05 0x32 0x10 0x30 0x11 0x30 0x0F 0x30 0x06 0x28 0x21 0x28 0x19 0x28 0x1D>;
		oplus,bpp-fod-parm = 		/bits/ 8 <0xff  0x48 0x55 0x48 0x50 0x48 0x55 0x48 0x53 0x48 0x5A 0x48 0x76 0xff 0xff 0xff 0xff 0xff 0xff 0xff 0xff
								0xff 0xff 0xff 0xff 0xff 0xff 0xff 0xff 0xff 0xff 0xff 0xff 0xff 0xff 0xff 0xff 0xff 0xff 0xff 0xff>;
		oplus,bpp-fod-parm-magcvr =	/bits/ 8 <0xff  0x48 0x5A 0x48 0x4E 0x48 0x55 0x48 0x5D 0x48 0x5A 0x48 0x70 0xff 0xff 0xff 0xff 0xff 0xff 0xff 0xff
								0xff 0xff 0xff 0xff 0xff 0xff 0xff 0xff 0xff 0xff 0xff 0xff 0xff 0xff 0xff 0xff 0xff 0xff 0xff 0xff>;
		oplus,epp-fod-parm =		/bits/ 8 <0xff  0x48 0x0A 0x48 0x41 0x46 0x32 0x46 0x37 0x46 0x3C 0x46 0x6E 0xff 0xff 0xff 0xff 0xff 0xff 0xff 0xff
								0xff 0xff 0xff 0xff 0xff 0xff 0xff 0xff 0xff 0xff 0xff 0xff 0xff 0xff 0xff 0xff 0xff 0xff 0xff 0xff>;
		oplus,epp-fod-parm-magcvr =	/bits/ 8 <0xff  0x48 0x0A 0x48 0x69 0x47 0x50 0x47 0x50 0x47 0x55 0x47 0x82 0xff 0xff 0xff 0xff 0xff 0xff 0xff 0xff
								0xff 0xff 0xff 0xff 0xff 0xff 0xff 0xff 0xff 0xff 0xff 0xff 0xff 0xff 0xff 0xff 0xff 0xff 0xff 0xff>;
		/*only fod parms*/
		oplus,disable-fod-parm =	/bits/ 8 <0xff 0xff 0xff 0xff 0xff 0xff 0xff 0xff 0xff 0xff 0xff 0xff 0xff 0xff 0xff 0xff 0xff 0xff 0xff 0xff
							  0xff 0xff 0xff 0xff 0xff 0xff 0xff 0xff 0xff 0xff 0xff 0xff 0xff 0xff 0xff 0xff 0xff 0xff 0xff 0xff>;

		oplus,bpp-vol-mv = <5500>;
		oplus,epp-vol-mv = <6000>;
		oplus,epp_plus-vol-mv = <6000>;
		oplus,vooc-vol-mv = <6400>;
		oplus,svooc-vol-mv = <10000>;
		oplus,fastchg-init-vout-mv = <6400>;
		oplus,full-bridge-vout-mv = <9200>;
		oplus,cp-open-offset-mv = <200>;
		oplus,cp-open-offset-min-mv = <100>;

		oplus,fastchg-max-soc = <94>;
		oplus,fastchg-max-temp = <440>;
		oplus,strategy_soc = <20 85 95>;

		/*
		 * | temp_min | temp_max | icl_curr | fcc_curr | need_wait |
		 */
		oplus,wls_epp_strategy =	<0 350 1500 2000 1
						 335 360 1200 1500 1
						 350 530 800 1000 1>;
		oplus,wls_epp_plus_strategy =	<0 330 1700 2200 1
						 310 350 1500 2000 1
						 335 360 1200 1600 1
						 350 530 800 1000 1>;

		/*
		 * | temp_min | temp_max | target_curr_ma | vol_max_mv | need wait |
		 * temp_min: Switch to the previous level when the temperature is lower
		 *           than this value.
		 * temp_max: Switch to the next level when the temperature is greater
		 *           than this value
		 * target_curr_ma: wls icl when vbat < vol_max_mv
		 * vol_max_mv: the last value is always 5000mV(must be greater than the max-vbat)
		 * need wait: not use here
		 */
		non_ffc_strategy {
			wls_bpp_strategy {
				strategy_low_battery {
					wls_temp_little_cold = <(-100) 0 750 5000 0>;
					wls_temp_cool =	<0 50 750 5000 0>;
					wls_temp_little_cool = <50 120 750 5000 0>;
					wls_temp_pre_normal = <120 160 750 5000 0>;
					wls_temp_normal = <160 350 750 5000 0>;
					wls_temp_normal_high = <350 450 750 5000 0>;
					wls_temp_warm = <450 530 750 5000 0>;
				};
				strategy_high_battery {
					wls_temp_little_cold = <(-100) 0 400 5000 0>;
					wls_temp_cool =	<0 50 750 5000 0>;
					wls_temp_little_cool = <50 120 750 5000 0>;
					wls_temp_pre_normal = <120 160 750 5000 0>;
					wls_temp_normal = <160 350 750 5000 0>;
					wls_temp_normal_high = <350 450 750 5000 0>;
					wls_temp_warm = <450 530 750 5000 0>;
				};
			};

			wls_epp_strategy {
				strategy_low_battery {
					wls_temp_little_cold = 	<(-100) 0 800 5000 0>;
					wls_temp_cool =		<0 50 1500 4405 0
								0 50 1100 4425 0
								0 50 800 5000 0>;
					wls_temp_little_cool = <50 120 1500 4405 0
								50 120 1100 4425 0
								50 120 800 5000 0>;
					wls_temp_pre_normal = <120 160 1500 4405 0
								120 160 1100 4425 0
								120 160 800 5000 0>;
					wls_temp_normal = <160 350 1500 4405 0
								160 350 1100 4425 0
								160 350 800 5000 0>;
					wls_temp_normal_high = 	<350 450 1500 4385 0
								350 450 1100 4405 0
								350 450 800 5000 0>;
					wls_temp_warm = <450 530 800 5000 0>;
				};
				strategy_high_battery {
					wls_temp_little_cold = 	<(-100) 0 800 5000 0>;
					wls_temp_cool =	<0 50 800 5000 0>;
					wls_temp_little_cool = <50 120 1100 4425 0
								50 120 800 5000 0>;
					wls_temp_pre_normal = <120 160 1500 4405 0
								120 160 1100 4425 0
								120 160 800 5000 0>;
					wls_temp_normal = <160 350 1500 4405 0
								160 350 1100 4425 0
								160 350 800 5000 0>;
					wls_temp_normal_high = 	<350 450 1500 4385 0
								350 450 1100 4405 0
								350 450 800 5000 0>;
					wls_temp_warm = <450 530 400 5000 0>;
				};
			};

			wls_epp_plus_strategy {
				strategy_low_battery {
					wls_temp_little_cold = 	<(-100) 0 800 5000 0>;
					wls_temp_cool =	<0 50 1700 4400 0
								0 50 1500 4405 0
								0 50 1100 4425 0
								0 50 800 5000 0>;
					wls_temp_little_cool = <50 120 1700 4400 0
								50 120 1500 4405 0
								50 120 1100 4425 0
								50 120 800 5000 0>;
					wls_temp_pre_normal = <120 160 1700 4400 0
								120 160 1500 4405 0
								120 160 1100 4425 0
								120 160 800 5000 0>;
					wls_temp_normal = <160 350 1700 4400 0
								160 350 1500 4405 0
								160 350 1100 4425 0
								160 350 800 5000 0>;
					wls_temp_normal_high = 	<350 450 1700 4400 0
								350 450 1500 4405 0
								350 450 1100 4425 0
								350 450 800 5000 0>;
					wls_temp_warm = <450 530 800 5000 0>;
				};
				strategy_high_battery {
					wls_temp_little_cold = 	<(-100) 0 800 5000 0>;
					wls_temp_cool =	<0 50 1700 4400 0
								0 50 1500 4405 0
								0 50 1100 4425 0
								0 50 800 5000 0>;
					wls_temp_little_cool = <50 120 1700 4400 0
								50 120 1500 4405 0
								50 120 1100 4425 0
								50 120 800 5000 0>;
					wls_temp_pre_normal = <120 160 1700 4400 0
								120 160 1500 4405 0
								120 160 1100 4425 0
								120 160 800 5000 0>;
					wls_temp_normal = <160 350 1700 4400 0
								160 350 1500 4405 0
								160 350 1100 4425 0
								160 350 800 5000 0>;
					wls_temp_normal_high = 	<350 450 1700 4400 0
								350 450 1500 4405 0
								350 450 1100 4425 0
								350 450 800 5000 0>;
					wls_temp_warm = <450 530 800 5000 0>;
				};
			};

			wls_airvooc_strategy {
				strategy_low_battery {
					wls_temp_little_cold = 	<(-100) 0 750 5000 0>;
					wls_temp_cool =	<0 50 1800 4395 0
								0 50 750 5000 0>;
					wls_temp_little_cool = <50 120 1800 4395 0
								50 120 750 5000 0>;
					wls_temp_pre_normal = <120 160 1800 4395 0
								120 160 750 5000 0>;
					wls_temp_normal = <160 350 1800 4395 0
								160 350 750 5000 0>;
					wls_temp_normal_high = 	<350 450 1800 4395 0
								350 450 750 5000 0>;
					wls_temp_warm = <450 530 750 5000 0>;
				};
				strategy_high_battery {
					wls_temp_little_cold = 	<(-100) 0 750 5000 0>;
					wls_temp_cool =	<0 50 1800 4395 0
								0 50 750 5000 0>;
					wls_temp_little_cool = <50 120 1800 4395 0
								50 120 750 5000 0>;
					wls_temp_pre_normal = <120 160 1800 4395 0
								120 160 750 5000 0>;
					wls_temp_normal = <160 350 1800 4395 0
								160 350 750 5000 0>;
					wls_temp_normal_high = 	<350 450 1800 4395 0
								350 450 750 5000 0>;
					wls_temp_warm = <450 530 750 5000 0>;
				};
			};

			wls_airsvooc_strategy {
				strategy_low_battery {
					wls_temp_little_cold = 	<(-100) 0 750 5000 0>;
					wls_temp_cool =	<0 50 1100 4425 0
								0 50 750 5000 0>;
					wls_temp_little_cool = <50 120 1800 4395 0
								50 120 750 5000 0>;
					wls_temp_pre_normal = <120 160 1800 4395 0
								120 160 750 5000 0>;
					wls_temp_normal = <160 350 1800 4395 0
								160 350 750 5000 0>;
					wls_temp_normal_high = 	<350 450 1100 4405 0
								350 450 750 5000 0>;
					wls_temp_warm = <450 530 750 5000 0>;
				};
				strategy_high_battery {
				wls_temp_little_cold = 	<(-100) 0 750 5000 0>;
					wls_temp_cool =	<0 50 1100 4425 0
								0 50 750 5000 0>;
					wls_temp_little_cool = <50 120 1800 4395 0
								50 120 750 5000 0>;
					wls_temp_pre_normal = <120 160 1800 4395 0
								120 160 750 5000 0>;
					wls_temp_normal = <160 350 1800 4395 0
								160 350 750 5000 0>;
					wls_temp_normal_high = 	<350 450 1100 4405 0
								350 450 750 5000 0>;
					wls_temp_warm = <450 530 750 5000 0>;
				};
			};
		};


		/*
		 * | temp_min | temp_max | target_curr_ma | vol_max_mv |need wait | soc_max |
		 *
		 * temp_min: Switch to the previous level when the temperature is lower
		 *           than this value. If it is 0, do not switch.
		 * temp_max: Switch to the next level when the temperature is greater
		 *           than this value
		 * target_curr_ma: Target current in this temperature range.
		 * vol_max_mv: Maximum battery voltage.
		 * need wait: 1:Need wait for a while after switching to the next level.
		 *            0:No need to wait after switching to the next level.
		 */
		wireless_fastchg_strategy {
			strategy_soc_0_to_30 {
				strategy_temp_0_to_50 =		<0 440 1250 4560 1
								 0 440 1000 4570 0>;
				strategy_temp_50_to_120 =	<50 420 2000 4560 1
								 50 440 1500 4560 1
								 50 440 1250 4560 1
								 50 440 1000 4570 0>;
				strategy_temp_120_to_160 = 	<120 350 2500 4560 1
								 340 375 2000 4560 1
								 360 410 1500 4560 1
								 400 430 1250 4560 1
								 430 440 1000 4560 0>;
				strategy_temp_160_to_400 =      <120 290 5000 4280 30
								 165 330 3500 4560 1
								 295 340 2500 4560 1
								 320 360 2370 4560 1
								 345 375 2050 4560 1
								 355 380 1750 4560 1
								 370 390 1500 4545 1
								 385 400 1250 4545 1
								 395 440 1000 4545 0>;
				strategy_temp_400_to_440 =      <120 290 5000 4280 30
								 165 330 3500 4560 1
								 295 340 2500 4560 1
								 320 360 2370 4560 1
								 345 375 2050 4530 1
								 355 380 1750 4530 1
								 370 390 1500 4530 1
								 385 400 1250 4530 1
								 395 440 1000 4530 0>;
			};

			strategy_soc_30_to_70 {
				strategy_temp_0_to_50 =		<0 440 1250 4560 1
								 0 440 1000 4570 0>;
				strategy_temp_50_to_120 =	<50 420 2000 4560 1
								 50 440 1500 4560 1
								 50 440 1250 4560 1
								 50 440 1000 4570 0>;
				strategy_temp_120_to_160 =	<120 350 2500 4560 1
								 340 375 2000 4560 1
								 360 410 1500 4560 1
								 400 430 1250 4560 1
								 430 440 1000 4560 0>;
				strategy_temp_160_to_400 =	<120 330 3500 4560 1
								 295 340 2500 4560 1
								 320 360 2370 4560 1
								 345 370 2050 4560 1
								 355 380 1750 4560 1
								 370 390 1500 4545 1
								 385 400 1250 4545 1
								 395 440 1000 4545 0>;
				strategy_temp_400_to_440 =	<120 330 3000 4560 1
								 295 340 2500 4560 1
								 320 360 2370 4560 1
								 345 370 2050 4530 1
								 355 380 1750 4530 1
								 370 390 1500 4530 1
								 385 400 1250 4530 1
								 395 440 1000 4530 0>;
			};

			strategy_soc_70_to_90 {
				strategy_temp_0_to_50 =		<0 440 1250 4140 1
								 0 440 1000 4570 0>;
				strategy_temp_50_to_120 =	<50 420 2000 4150 1
								 50 440 1500 4150 1
								 50 440 1250 4510 1
								 50 440 1000 4570 0>;
				strategy_temp_120_to_160 =	<120 350 2500 4150 1
								 340 375 2000 4330 1
								 360 410 1500 4330 1
								 400 430 1250 4540 1
								 430 440 1000 4560 0>;
				strategy_temp_160_to_400 =	<120 340 2500 4545 1
								 320 360 2370 4545 1
								 345 375 2050 4545 1
								 355 380 1750 4545 1
								 370 390 1500 4545 1
								 385 400 1250 4545 1
								 395 440 1000 4545 0>;
				strategy_temp_400_to_440 =	<120 340 2500 4530 1
								 320 360 2370 4530 1
								 345 375 2050 4530 1
								 355 380 1750 4530 1
								 370 390 1500 4530 1
								 385 400 1250 4530 1
								 395 440 1000 4530 0>;
			};
		};

		wireless_fastchg_strategy_magcvr {
			strategy_soc_0_to_30 {
				strategy_temp_0_to_50 =		<0 440 1250 4560 1
								 0 440 1000 4570 0>;
				strategy_temp_50_to_120 =	<50 420 2000 4560 1
								 50 440 1500 4560 1
								 50 440 1250 4560 1
								 50 440 1000 4570 0>;
				strategy_temp_120_to_160 = 	<120 350 2500 4560 1
								 340 375 2000 4560 1
								 360 410 1500 4560 1
								 400 430 1250 4560 1
								 430 440 1000 4560 0>;
				strategy_temp_160_to_400 =      <120 290 5000 4280 30
								 165 296 3500 4560 1
								 295 325 2500 4560 1
								 310 362 2250 4560 1
								 315 380 2000 4560 1
								 325 390 1750 4560 1
								 380 391 1600 4560 1
								 385 415 1250 4545 1
								 390 440 1000 4545 0>;
				strategy_temp_400_to_440 =      <120 290 5000 4280 30
								 165 296 3500 4560 1
								 295 325 2500 4560 1
								 310 362 2250 4560 1
								 315 380 2000 4530 1
								 325 390 1750 4530 1
								 370 391 1600 4530 1
								 385 415 1250 4530 1
								 390 440 1000 4530 0>;
			};

			strategy_soc_30_to_70 {
				strategy_temp_0_to_50 =		<0 440 1250 4560 1
								 0 440 1000 4570 0>;
				strategy_temp_50_to_120 =	<50 420 2000 4560 1
								 50 440 1500 4560 1
								 50 440 1250 4560 1
								 50 440 1000 4570 0>;
				strategy_temp_120_to_160 =	<120 350 2500 4560 1
								 340 375 2000 4560 1
								 360 410 1500 4560 1
								 400 430 1250 4560 1
								 430 440 1000 4560 0>;
				strategy_temp_160_to_400 =	<285 300 3000 4560 1
								 295 325 2500 4560 1
								 310 362 2250 4560 1
								 315 380 2000 4560 1
								 325 390 1750 4560 1
								 370 391 1600 4560 1
								 385 415 1250 4545 1
								 390 440 1000 4545 0>;
				strategy_temp_400_to_440 =	<285 296 3500 4560 1
								 295 325 2500 4560 1
								 310 362 2250 4560 1
								 315 380 2000 4530 1
								 325 390 1750 4530 1
								 370 391 1600 4530 1
								 385 415 1250 4530 1
								 390 440 1000 4530 0>;
			};

			strategy_soc_70_to_90 {
				strategy_temp_0_to_50 =		<0 440 1250 4140 1
								 0 440 1000 4570 0>;
				strategy_temp_50_to_120 =	<50 420 2000 4150 1
								 50 440 1500 4150 1
								 50 440 1250 4510 1
								 50 440 1000 4570 0>;
				strategy_temp_120_to_160 =	<120 350 2500 4150 1
								 340 375 2000 4330 1
								 360 410 1500 4330 1
								 400 430 1250 4540 1
								 430 440 1000 4560 0>;
				strategy_temp_160_to_400 =	<120 310 2500 4545 1
								 305 357 2250 4545 1
								 345 375 2000 4545 1
								 355 390 1750 4545 1
								 370 391 1500 4545 1
								 385 400 1250 4545 1
								 395 440 1000 4545 0>;
				strategy_temp_400_to_440 =	<120 310 2500 4530 1
								 305 357 2250 4530 1
								 345 380 2000 4550 1
								 355 390 1750 4530 1
								 370 391 1500 4530 1
								 385 400 1250 4530 1
								 395 440 1000 4530 0>;
			};
		};

		/*
		 * | max_batt_volt | max_current | min_current | end
		 *
		 * max_batt_volt: Maximum battery voltage.
		 * max_current: The maximum current in this interval.
		 * min_current: The result obtained by subtracting 1A from the
		 *				minimum current in this interval. Minimum not less than 1A.
		 * exit: Whether the curve ends or not.
		 */
		wireless_bcc_table {
			bcc_soc_0_to_30 {
				bcc_temp_0_to_50 =	<4184 2000 1000 0
							 4454 1500 1000 0
							 4460 1000 1000 1>;
				bcc_temp_50_to_120 =	<4184 2500 1000 0
							 4454 2000 1000 0
							 4460 1000 1000 1>;
				bcc_temp_120_to_160 =	<4184 5000 3500 0
							 4484 4000 3000 0
							 4514 3000 1000 0
							 4520 1300 1000 1>;
				bcc_temp_160_to_400 =	<4184 5000 3500 0
							 4454 4000 3000 0
							 4514 3000 1000 0
							 4520 1300 1000 1>;
				bcc_temp_400_to_440 =	<4184 5000 3500 0
							 4454 4000 3000 0
							 4514 3000 1000 0
							 4520 1300 1000 1>;
			};

			bcc_soc_30_to_70 {
				bcc_temp_0_to_50 =	<4454 1500 1000 0
							 4460 1000 1000 1>;
				bcc_temp_50_to_120 =	<4454 2000 1000 0
							 4460 1000 1000 1>;
				bcc_temp_120_to_160 =	<4484 4000 3000 0
							 4514 3000 1000 0
							 4520 1300 1000 1>;
				bcc_temp_160_to_400 =	<4484 4000 3000 0
							 4514 3000 1000 0
							 4520 1300 1000 1>;
				bcc_temp_400_to_440 =	<4484 4000 3000 0
							 4514 3000 1000 0
							 4520 1300 1000 1>;
			};

			bcc_soc_70_to_90 {
				bcc_temp_0_to_50 =	<4460 1000 1000 1>;
				bcc_temp_50_to_120 =	<4460 1000 1000 1>;
				bcc_temp_120_to_160 =	<4514 3000 1000 0
							 4520 1300 1000 1>;
				bcc_temp_160_to_400 =	<4514 3000 1000 0
							 4520 1300 1000 1>;
				bcc_temp_400_to_440 =	<4514 3000 1000 0
							 4520 1300 1000 1>;
			};
		};
	};
};

&soc {
	oplus_virtual_rx: oplus,virtual_rx {
		compatible = "oplus,virtual_rx";
		oplus,rx_ic = <&oplus_rx_nu1669>;
		oplus,rx_ic_index = <0>;
		oplus,rx_ic_func_group = <&nu1669_rx_groups>;
		oplus,ic_type = <OPLUS_CHG_IC_VIRTUAL_RX>;
		oplus,ic_index = <0>;
	};

	/*oplus_virtual_cp: oplus,virtual_cp {
		compatible = "oplus,virtual_cp";
		oplus,cp_ic = <&oplus_cp_nu1669>;
		oplus,cp_ic_connect = <OPLUS_CHG_IC_CONNECT_PARALLEL>;
		oplus,main_cp = <0>;
		oplus,input_curr_max_ma = <5000>;
		oplus,cp_ic_func_group = <&nu1669_cp_groups>;
		oplus,ic_type = <OPLUS_CHG_IC_VIRTUAL_CP>;
		oplus,ic_index = <0>;
	};*/
};

&pio {
	rx_event_default: rx_event_default {
		pins_cmd_dat {
			pinmux = <PINMUX_GPIO62__FUNC_GPIO62>;
			input-enable;
			bias-pull-up;
		};
	};

	rx_con_default: rx_con_default {
		pins_cmd_dat {
			pinmux = <PINMUX_GPIO82__FUNC_GPIO82>;
			input-enable;
			bias-pull-down = <MTK_PUPD_SET_R1R0_11>;
		};
	};

	rx_en_sleep: rx_en_sleep {
		pins_cmd_dat {
			pinmux = <PINMUX_GPIO81__FUNC_GPIO81>;
			bias-pull-up = <MTK_PUPD_SET_R1R0_11>;
			output-high;
		};
	};
	rx_en_active: rx_en_active {
		pins_cmd_dat {
			pinmux = <PINMUX_GPIO81__FUNC_GPIO81>;
			bias-pull-down = <MTK_PUPD_SET_R1R0_11>;
			output-low;
		};
	};

	insert_dis_active: insert_dis_active {
		pins_cmd_dat {
			pinmux = <PINMUX_GPIO80__FUNC_GPIO80>;
			bias-pull-up = <MTK_PUPD_SET_R1R0_11>;
			output-high;
		};
	};
	insert_dis_sleep: insert_dis_sleep {
		pins_cmd_dat {
			pinmux = <PINMUX_GPIO80__FUNC_GPIO80>;
			bias-pull-down = <MTK_PUPD_SET_R1R0_11>;
			output-low;
		};
	};
};

&i2c13 {
	status = "okay";
	clock-frequency = <400000>;

	oplus_nu1669: oplus,nu1669@36 {
		status = "ok";
		compatible = "oplus,rx-nu1669";
		reg = <0x36>;
		#address-cells = <1>;
		#size-cells = <0>;
		oplus,nor_ic = <&oplus_virtual_buck>;

		oplus,support_epp_11w;

		oplus,rx_event-gpio = <&pio 62 0x00>;//check
		oplus,rx_con-gpio = <&pio 82 0x00>;//check
		oplus,rx_en-gpio = <&pio 81 0x00>;//vt-sleep check
		oplus,insert_dis-gpio = <&pio 80 0x00>;//wls force pd check
		pinctrl-names = "rx_event_default", "rx_con_default",
				"rx_en_sleep", "rx_en_active",
				"insert_dis_active", "insert_dis_sleep";
		pinctrl-0 = <&rx_event_default>;
		pinctrl-1 = <&rx_con_default>;
		pinctrl-2 = <&rx_en_sleep>;
		pinctrl-3 = <&rx_en_active>;
		pinctrl-4 = <&insert_dis_active>;
		pinctrl-5 = <&insert_dis_sleep>;

		oplus_rx_nu1669: oplus,rx_nu1669 {
			oplus,ic_type = <OPLUS_CHG_IC_RX>;
			oplus,ic_index = <0>;
		};
	};
};

/* for pd common charger */
&ssusb {
		usb-psy-name = "mtk-master-charger";
		typec-name = "rt-pd-manager";
		typec-port-name = "port0";
};

&i2c5 {
		mediatek,fifo-use-polling;
		mediatek,request-cpu-qos;
};

&soc {
	oplus_chg_plc: oplus,plc_charge {
		compatible = "oplus,plc_charge";
		oplus,plc_support = <CHG_PROTOCOL_UFCS>;
		oplus,plc_soc = <90>;
		oplus,plc_strategy-data = <&buck_simple_strategy>;
		oplus,plc_strategy-names = "default";

		oplus_ufcs_step_strategy: oplus_ufcs_step_strategy {
			oplus,strategy_type = <PLC_STRATEGY_STEP>;
		};

		third_ufcs_simple_strategy: third_ufcs_simple_strategy {
			oplus,strategy_type = <PLC_STRATEGY_SIMPLE>;
			oplus,strategy_data {
				strategy_curr_ma = <1000 1500>;
			};
		};

		pps_simple_strategy: pps_simple_strategy {
			oplus,strategy_type = <PLC_STRATEGY_SIMPLE>;
			oplus,strategy_data {
				strategy_curr_ma = <1000 1500>;
			};
		};

		svooc_simple_strategy: svooc_simple_strategy {
			oplus,strategy_type = <PLC_STRATEGY_SIMPLE>;
			oplus,strategy_data {
				strategy_curr_ma = <1000 1500>;
			};
		};

		vooc_simple_strategy: vooc_simple_strategy {
			oplus,strategy_type = <PLC_STRATEGY_SIMPLE>;
			oplus,strategy_data {
				strategy_curr_ma = <2000 3000>;
			};
		};

		buck_simple_strategy: buck_simple_strategy {
			oplus,strategy_type = <PLC_STRATEGY_SIMPLE>;
		};
	};
};
//#endif OPLUS_FEATURE_CHG_BASIC /*for wls charging config*/
